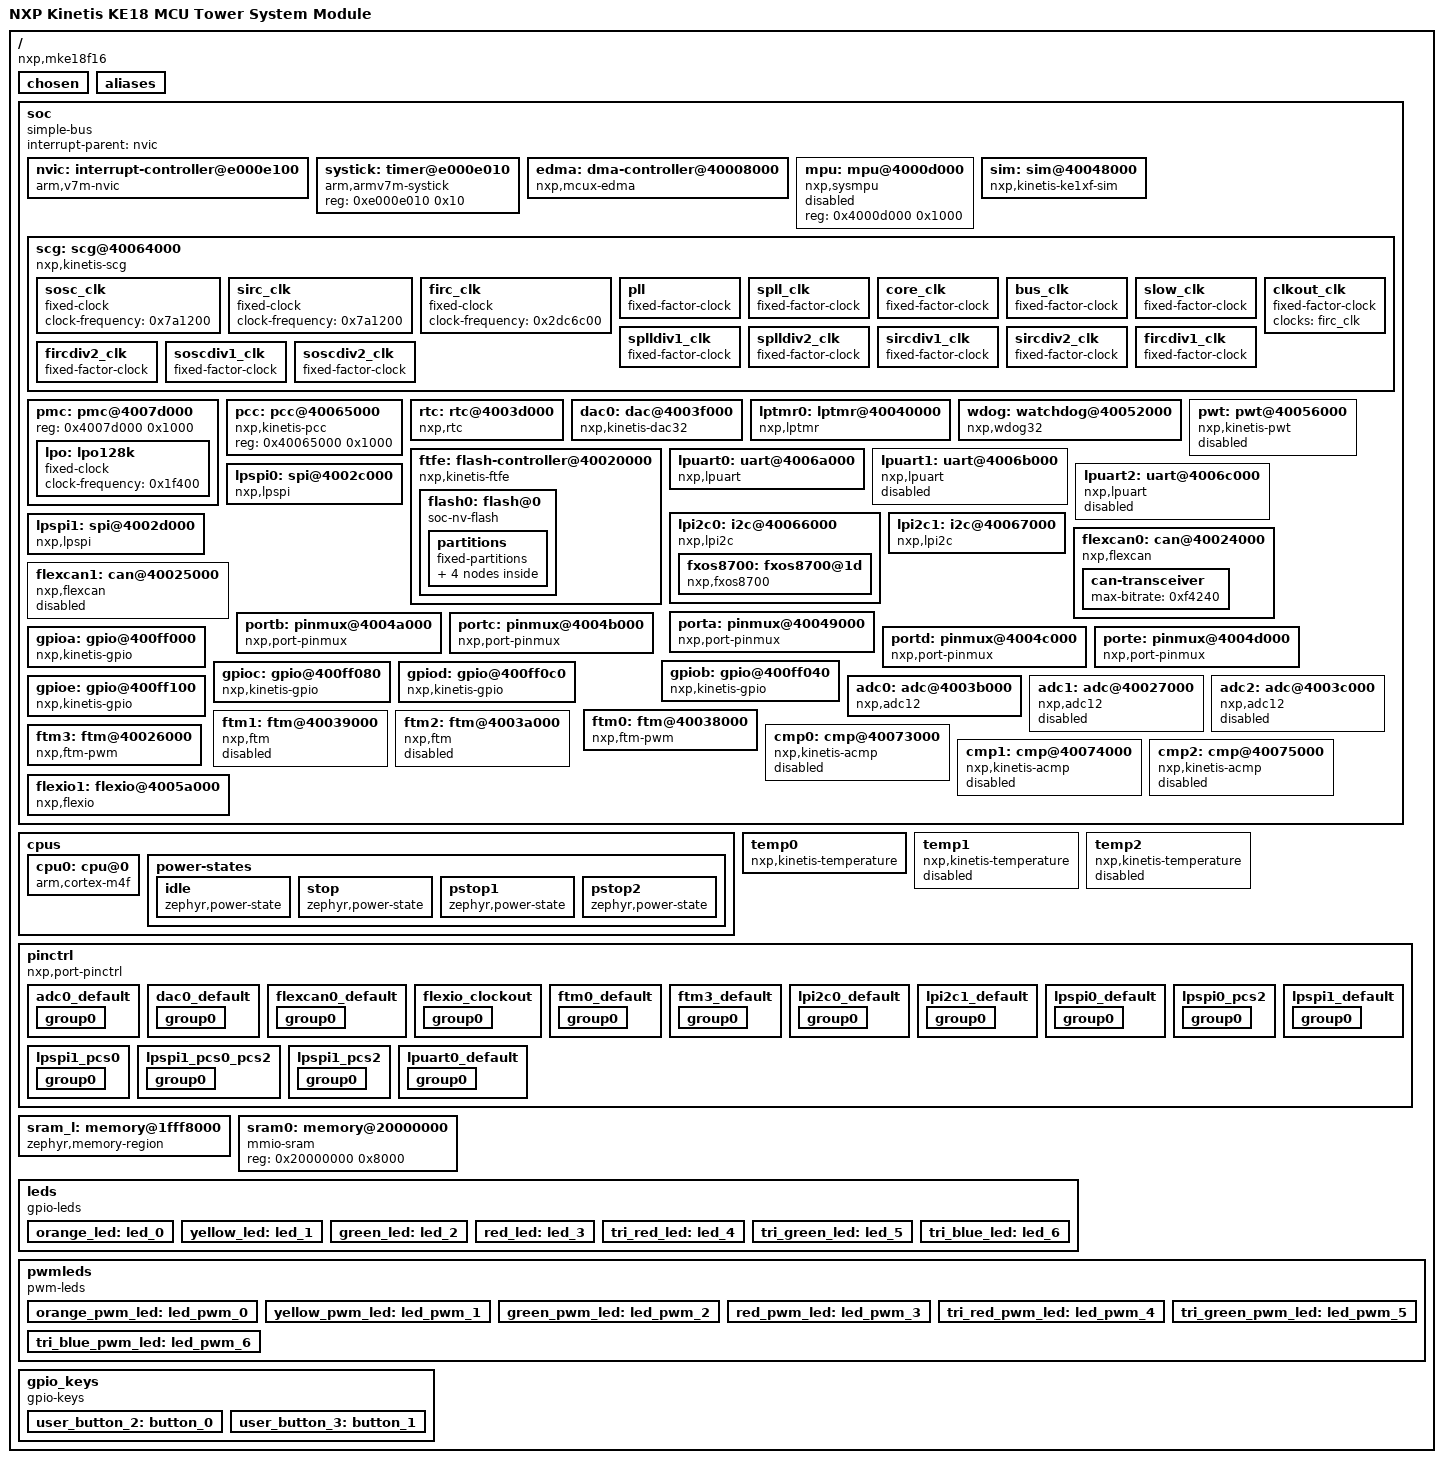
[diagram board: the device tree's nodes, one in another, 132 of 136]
/dts-v1/;

/* node '/' defined in zephyr/dts/common/skeleton.dtsi:9 */
/ {
	#address-cells = < 0x1 >;                           /* in zephyr/dts/common/skeleton.dtsi:10 */
	#size-cells = < 0x1 >;                              /* in zephyr/dts/common/skeleton.dtsi:11 */
	model = "NXP Kinetis KE18 MCU Tower System Module"; /* in zephyr/boards/nxp/twr_ke18f/twr_ke18f.dts:16 */
	compatible = "nxp,mke18f16",
	             "nxp,ke18f",
	             "nxp,ke1xf";                           /* in zephyr/boards/nxp/twr_ke18f/twr_ke18f.dts:17 */

	/* node '/chosen' defined in zephyr/dts/common/skeleton.dtsi:13 */
	chosen {
		zephyr,flash-controller = &ftfe;          /* in zephyr/dts/arm/nxp/nxp_ke1xf.dtsi:20 */
		zephyr,sram = &sram0;                     /* in zephyr/boards/nxp/twr_ke18f/twr_ke18f.dts:48 */
		zephyr,flash = &flash0;                   /* in zephyr/boards/nxp/twr_ke18f/twr_ke18f.dts:49 */
		zephyr,code-partition = &slot0_partition; /* in zephyr/boards/nxp/twr_ke18f/twr_ke18f.dts:50 */
		zephyr,uart-mcumgr = &lpuart0;            /* in zephyr/boards/nxp/twr_ke18f/twr_ke18f.dts:51 */
		zephyr,console = &lpuart0;                /* in zephyr/boards/nxp/twr_ke18f/twr_ke18f.dts:52 */
		zephyr,shell-uart = &lpuart0;             /* in zephyr/boards/nxp/twr_ke18f/twr_ke18f.dts:53 */
		zephyr,uart-pipe = &lpuart0;              /* in zephyr/boards/nxp/twr_ke18f/twr_ke18f.dts:54 */
		zephyr,canbus = &flexcan0;                /* in zephyr/boards/nxp/twr_ke18f/twr_ke18f.dts:55 */
	};

	/* node '/aliases' defined in zephyr/dts/common/skeleton.dtsi:15 */
	aliases {
		watchdog0 = &wdog;                  /* in zephyr/dts/arm/nxp/nxp_ke1xf.dtsi:16 */
		led0 = &orange_led;                 /* in zephyr/boards/nxp/twr_ke18f/twr_ke18f.dts:20 */
		led1 = &yellow_led;                 /* in zephyr/boards/nxp/twr_ke18f/twr_ke18f.dts:21 */
		led2 = &green_led;                  /* in zephyr/boards/nxp/twr_ke18f/twr_ke18f.dts:22 */
		led3 = &red_led;                    /* in zephyr/boards/nxp/twr_ke18f/twr_ke18f.dts:23 */
		led4 = &tri_red_led;                /* in zephyr/boards/nxp/twr_ke18f/twr_ke18f.dts:24 */
		led5 = &tri_green_led;              /* in zephyr/boards/nxp/twr_ke18f/twr_ke18f.dts:25 */
		led6 = &tri_blue_led;               /* in zephyr/boards/nxp/twr_ke18f/twr_ke18f.dts:26 */
		pwm-led0 = &orange_pwm_led;         /* in zephyr/boards/nxp/twr_ke18f/twr_ke18f.dts:27 */
		pwm-led1 = &yellow_pwm_led;         /* in zephyr/boards/nxp/twr_ke18f/twr_ke18f.dts:28 */
		pwm-led2 = &green_pwm_led;          /* in zephyr/boards/nxp/twr_ke18f/twr_ke18f.dts:29 */
		pwm-led3 = &red_pwm_led;            /* in zephyr/boards/nxp/twr_ke18f/twr_ke18f.dts:30 */
		red-pwm-led = &tri_red_pwm_led;     /* in zephyr/boards/nxp/twr_ke18f/twr_ke18f.dts:31 */
		green-pwm-led = &tri_green_pwm_led; /* in zephyr/boards/nxp/twr_ke18f/twr_ke18f.dts:32 */
		blue-pwm-led = &tri_blue_pwm_led;   /* in zephyr/boards/nxp/twr_ke18f/twr_ke18f.dts:33 */
		sw0 = &user_button_3;               /* in zephyr/boards/nxp/twr_ke18f/twr_ke18f.dts:34 */
		sw1 = &user_button_2;               /* in zephyr/boards/nxp/twr_ke18f/twr_ke18f.dts:35 */
		magn0 = &fxos8700;                  /* in zephyr/boards/nxp/twr_ke18f/twr_ke18f.dts:36 */
		accel0 = &fxos8700;                 /* in zephyr/boards/nxp/twr_ke18f/twr_ke18f.dts:37 */
		mcuboot-button0 = &user_button_3;   /* in zephyr/boards/nxp/twr_ke18f/twr_ke18f.dts:38 */
	};

	/* node '/soc' defined in zephyr/dts/arm/armv7-m.dtsi:6 */
	soc {
		#address-cells = < 0x1 >;     /* in zephyr/dts/arm/armv7-m.dtsi:7 */
		#size-cells = < 0x1 >;        /* in zephyr/dts/arm/armv7-m.dtsi:8 */
		compatible = "simple-bus";    /* in zephyr/dts/arm/armv7-m.dtsi:9 */
		interrupt-parent = < &nvic >; /* in zephyr/dts/arm/armv7-m.dtsi:10 */
		ranges;                       /* in zephyr/dts/arm/armv7-m.dtsi:11 */

		/* node '/soc/interrupt-controller@e000e100' defined in zephyr/dts/arm/armv7-m.dtsi:13 */
		nvic: interrupt-controller@e000e100 {
			#address-cells = < 0x1 >;            /* in zephyr/dts/arm/armv7-m.dtsi:14 */
			compatible = "arm,v7m-nvic";         /* in zephyr/dts/arm/armv7-m.dtsi:15 */
			reg = < 0xe000e100 0xc00 >;          /* in zephyr/dts/arm/armv7-m.dtsi:16 */
			interrupt-controller;                /* in zephyr/dts/arm/armv7-m.dtsi:17 */
			#interrupt-cells = < 0x2 >;          /* in zephyr/dts/arm/armv7-m.dtsi:18 */
			arm,num-irq-priority-bits = < 0x4 >; /* in zephyr/dts/arm/nxp/nxp_ke1xf.dtsi:612 */
			phandle = < 0x1 >;                   /* in zephyr/dts/arm/armv7-m.dtsi:10 */
		};

		/* node '/soc/timer@e000e010' defined in zephyr/dts/arm/armv7-m.dtsi:21 */
		systick: timer@e000e010 {
			compatible = "arm,armv7m-systick"; /* in zephyr/dts/arm/armv7-m.dtsi:22 */
			reg = < 0xe000e010 0x10 >;         /* in zephyr/dts/arm/armv7-m.dtsi:23 */
		};

		/* node '/soc/dma-controller@40008000' defined in zephyr/dts/arm/nxp/nxp_ke1xf.dtsi:100 */
		edma: dma-controller@40008000 {
			compatible = "nxp,mcux-edma"; /* in zephyr/dts/arm/nxp/nxp_ke1xf.dtsi:101 */
			nxp,version = < 0x2 >;        /* in zephyr/dts/arm/nxp/nxp_ke1xf.dtsi:102 */
			dma-channels = < 0x10 >;      /* in zephyr/dts/arm/nxp/nxp_ke1xf.dtsi:103 */
			dma-requests = < 0x40 >;      /* in zephyr/dts/arm/nxp/nxp_ke1xf.dtsi:104 */
			nxp,mem2mem;                  /* in zephyr/dts/arm/nxp/nxp_ke1xf.dtsi:105 */
			reg = < 0x40008000 0x1000 >,
			      < 0x40021000 0x1000 >;  /* in zephyr/dts/arm/nxp/nxp_ke1xf.dtsi:106 */
			interrupts = < 0x0 0x0 >,
			             < 0x1 0x0 >,
			             < 0x2 0x0 >,
			             < 0x3 0x0 >,
			             < 0x4 0x0 >,
			             < 0x5 0x0 >,
			             < 0x6 0x0 >,
			             < 0x7 0x0 >,
			             < 0x8 0x0 >,
			             < 0x9 0x0 >,
			             < 0xa 0x0 >,
			             < 0xb 0x0 >,
			             < 0xc 0x0 >,
			             < 0xd 0x0 >,
			             < 0xe 0x0 >,
			             < 0xf 0x0 >,
			             < 0x10 0x0 >;    /* in zephyr/dts/arm/nxp/nxp_ke1xf.dtsi:107 */
			#dma-cells = < 0x2 >;         /* in zephyr/dts/arm/nxp/nxp_ke1xf.dtsi:113 */
			status = "okay";              /* in zephyr/boards/nxp/twr_ke18f/twr_ke18f.dts:342 */
			phandle = < 0xc >;            /* in zephyr/dts/arm/nxp/nxp_ke1xf.dtsi:333 */
		};

		/* node '/soc/mpu@4000d000' defined in zephyr/dts/arm/nxp/nxp_ke1xf.dtsi:116 */
		mpu: mpu@4000d000 {
			compatible = "nxp,sysmpu";   /* in zephyr/dts/arm/nxp/nxp_ke1xf.dtsi:117 */
			reg = < 0x4000d000 0x1000 >; /* in zephyr/dts/arm/nxp/nxp_ke1xf.dtsi:118 */
			status = "disabled";         /* in zephyr/dts/arm/nxp/nxp_ke1xf.dtsi:119 */
		};

		/* node '/soc/sim@40048000' defined in zephyr/dts/arm/nxp/nxp_ke1xf.dtsi:122 */
		sim: sim@40048000 {
			compatible = "nxp,kinetis-ke1xf-sim"; /* in zephyr/dts/arm/nxp/nxp_ke1xf.dtsi:123 */
			reg = < 0x40048000 0x1000 >;          /* in zephyr/dts/arm/nxp/nxp_ke1xf.dtsi:124 */
			clkout-source = < 0x1 >;              /* in zephyr/boards/nxp/twr_ke18f/twr_ke18f.dts:167 */
			clkout-divider = < 0x0 >;             /* in zephyr/boards/nxp/twr_ke18f/twr_ke18f.dts:168 */
		};

		/* node '/soc/scg@40064000' defined in zephyr/dts/arm/nxp/nxp_ke1xf.dtsi:127 */
		scg: scg@40064000 {
			compatible = "nxp,kinetis-scg"; /* in zephyr/dts/arm/nxp/nxp_ke1xf.dtsi:128 */
			reg = < 0x40064000 0x1000 >;    /* in zephyr/dts/arm/nxp/nxp_ke1xf.dtsi:129 */
			#clock-cells = < 0x1 >;         /* in zephyr/dts/arm/nxp/nxp_ke1xf.dtsi:130 */
			sosc-mode = < 0x4 >;            /* in zephyr/boards/nxp/twr_ke18f/twr_ke18f.dts:172 */
			phandle = < 0x8 >;              /* in zephyr/dts/arm/nxp/nxp_ke1xf.dtsi:280 */

			/* node '/soc/scg@40064000/sosc_clk' defined in zephyr/dts/arm/nxp/nxp_ke1xf.dtsi:132 */
			sosc_clk: sosc_clk {
				compatible = "fixed-clock";     /* in zephyr/dts/arm/nxp/nxp_ke1xf.dtsi:133 */
				#clock-cells = < 0x0 >;         /* in zephyr/dts/arm/nxp/nxp_ke1xf.dtsi:135 */
				status = "okay";                /* in zephyr/boards/nxp/twr_ke18f/twr_ke18f.dts:175 */
				clock-frequency = < 0x7a1200 >; /* in zephyr/boards/nxp/twr_ke18f/twr_ke18f.dts:176 */
				phandle = < 0x2 >;              /* in zephyr/dts/arm/nxp/nxp_ke1xf.dtsi:152 */
			};

			/* node '/soc/scg@40064000/sirc_clk' defined in zephyr/dts/arm/nxp/nxp_ke1xf.dtsi:138 */
			sirc_clk: sirc_clk {
				compatible = "fixed-clock";     /* in zephyr/dts/arm/nxp/nxp_ke1xf.dtsi:139 */
				clock-frequency = < 0x7a1200 >; /* in zephyr/dts/arm/nxp/nxp_ke1xf.dtsi:140 */
				#clock-cells = < 0x0 >;         /* in zephyr/dts/arm/nxp/nxp_ke1xf.dtsi:141 */
				phandle = < 0x7 >;              /* in zephyr/dts/arm/nxp/nxp_ke1xf.dtsi:209 */
			};

			/* node '/soc/scg@40064000/firc_clk' defined in zephyr/dts/arm/nxp/nxp_ke1xf.dtsi:144 */
			firc_clk: firc_clk {
				compatible = "fixed-clock";      /* in zephyr/dts/arm/nxp/nxp_ke1xf.dtsi:145 */
				clock-frequency = < 0x2dc6c00 >; /* in zephyr/dts/arm/nxp/nxp_ke1xf.dtsi:146 */
				#clock-cells = < 0x0 >;          /* in zephyr/dts/arm/nxp/nxp_ke1xf.dtsi:147 */
				phandle = < 0x6 >;               /* in zephyr/dts/arm/nxp/nxp_ke1xf.dtsi:189 */
			};

			/* node '/soc/scg@40064000/pll' defined in zephyr/dts/arm/nxp/nxp_ke1xf.dtsi:150 */
			pll: pll {
				compatible = "fixed-factor-clock"; /* in zephyr/dts/arm/nxp/nxp_ke1xf.dtsi:151 */
				clocks = < &sosc_clk >;            /* in zephyr/dts/arm/nxp/nxp_ke1xf.dtsi:152 */
				clock-div = < 0x1 >;               /* in zephyr/dts/arm/nxp/nxp_ke1xf.dtsi:153 */
				#clock-cells = < 0x0 >;            /* in zephyr/dts/arm/nxp/nxp_ke1xf.dtsi:155 */
				clock-mult = < 0x1e >;             /* in zephyr/boards/nxp/twr_ke18f/twr_ke18f.dts:180 */
				phandle = < 0x3 >;                 /* in zephyr/dts/arm/nxp/nxp_ke1xf.dtsi:160 */
			};

			/* node '/soc/scg@40064000/spll_clk' defined in zephyr/dts/arm/nxp/nxp_ke1xf.dtsi:158 */
			spll_clk: spll_clk {
				compatible = "fixed-factor-clock"; /* in zephyr/dts/arm/nxp/nxp_ke1xf.dtsi:159 */
				clocks = < &pll >;                 /* in zephyr/dts/arm/nxp/nxp_ke1xf.dtsi:160 */
				clock-div = < 0x2 >;               /* in zephyr/dts/arm/nxp/nxp_ke1xf.dtsi:161 */
				#clock-cells = < 0x0 >;            /* in zephyr/dts/arm/nxp/nxp_ke1xf.dtsi:162 */
				phandle = < 0x4 >;                 /* in zephyr/boards/nxp/twr_ke18f/twr_ke18f.dts:184 */
			};

			/* node '/soc/scg@40064000/core_clk' defined in zephyr/dts/arm/nxp/nxp_ke1xf.dtsi:165 */
			core_clk: core_clk {
				compatible = "fixed-factor-clock"; /* in zephyr/dts/arm/nxp/nxp_ke1xf.dtsi:166 */
				clock-div = < 0x1 >;               /* in zephyr/dts/arm/nxp/nxp_ke1xf.dtsi:168 */
				#clock-cells = < 0x0 >;            /* in zephyr/dts/arm/nxp/nxp_ke1xf.dtsi:169 */
				clocks = < &spll_clk >;            /* in zephyr/boards/nxp/twr_ke18f/twr_ke18f.dts:184 */
				phandle = < 0x5 >;                 /* in zephyr/dts/arm/nxp/nxp_ke1xf.dtsi:174 */
			};

			/* node '/soc/scg@40064000/bus_clk' defined in zephyr/dts/arm/nxp/nxp_ke1xf.dtsi:172 */
			bus_clk: bus_clk {
				compatible = "fixed-factor-clock"; /* in zephyr/dts/arm/nxp/nxp_ke1xf.dtsi:173 */
				clocks = < &core_clk >;            /* in zephyr/dts/arm/nxp/nxp_ke1xf.dtsi:174 */
				#clock-cells = < 0x0 >;            /* in zephyr/dts/arm/nxp/nxp_ke1xf.dtsi:176 */
				clock-div = < 0x2 >;               /* in zephyr/boards/nxp/twr_ke18f/twr_ke18f.dts:188 */
			};

			/* node '/soc/scg@40064000/slow_clk' defined in zephyr/dts/arm/nxp/nxp_ke1xf.dtsi:179 */
			slow_clk: slow_clk {
				compatible = "fixed-factor-clock"; /* in zephyr/dts/arm/nxp/nxp_ke1xf.dtsi:180 */
				clocks = < &core_clk >;            /* in zephyr/dts/arm/nxp/nxp_ke1xf.dtsi:181 */
				#clock-cells = < 0x0 >;            /* in zephyr/dts/arm/nxp/nxp_ke1xf.dtsi:183 */
				clock-div = < 0x5 >;               /* in zephyr/boards/nxp/twr_ke18f/twr_ke18f.dts:192 */
			};

			/* node '/soc/scg@40064000/clkout_clk' defined in zephyr/dts/arm/nxp/nxp_ke1xf.dtsi:186 */
			clkout_clk: clkout_clk {
				compatible = "fixed-factor-clock"; /* in zephyr/dts/arm/nxp/nxp_ke1xf.dtsi:187 */
				clocks = < &firc_clk >;            /* in zephyr/dts/arm/nxp/nxp_ke1xf.dtsi:189 */
				#clock-cells = < 0x0 >;            /* in zephyr/dts/arm/nxp/nxp_ke1xf.dtsi:190 */
				status = "okay";                   /* in zephyr/boards/nxp/twr_ke18f/twr_ke18f.dts:196 */
			};

			/* node '/soc/scg@40064000/splldiv1_clk' defined in zephyr/dts/arm/nxp/nxp_ke1xf.dtsi:193 */
			splldiv1_clk: splldiv1_clk {
				compatible = "fixed-factor-clock"; /* in zephyr/dts/arm/nxp/nxp_ke1xf.dtsi:194 */
				clocks = < &spll_clk >;            /* in zephyr/dts/arm/nxp/nxp_ke1xf.dtsi:195 */
				#clock-cells = < 0x0 >;            /* in zephyr/dts/arm/nxp/nxp_ke1xf.dtsi:197 */
				clock-div = < 0x1 >;               /* in zephyr/boards/nxp/twr_ke18f/twr_ke18f.dts:200 */
			};

			/* node '/soc/scg@40064000/splldiv2_clk' defined in zephyr/dts/arm/nxp/nxp_ke1xf.dtsi:200 */
			splldiv2_clk: splldiv2_clk {
				compatible = "fixed-factor-clock"; /* in zephyr/dts/arm/nxp/nxp_ke1xf.dtsi:201 */
				clocks = < &spll_clk >;            /* in zephyr/dts/arm/nxp/nxp_ke1xf.dtsi:202 */
				#clock-cells = < 0x0 >;            /* in zephyr/dts/arm/nxp/nxp_ke1xf.dtsi:204 */
				clock-div = < 0x2 >;               /* in zephyr/boards/nxp/twr_ke18f/twr_ke18f.dts:204 */
			};

			/* node '/soc/scg@40064000/sircdiv1_clk' defined in zephyr/dts/arm/nxp/nxp_ke1xf.dtsi:207 */
			sircdiv1_clk: sircdiv1_clk {
				compatible = "fixed-factor-clock"; /* in zephyr/dts/arm/nxp/nxp_ke1xf.dtsi:208 */
				clocks = < &sirc_clk >;            /* in zephyr/dts/arm/nxp/nxp_ke1xf.dtsi:209 */
				#clock-cells = < 0x0 >;            /* in zephyr/dts/arm/nxp/nxp_ke1xf.dtsi:211 */
				clock-div = < 0x1 >;               /* in zephyr/boards/nxp/twr_ke18f/twr_ke18f.dts:208 */
			};

			/* node '/soc/scg@40064000/sircdiv2_clk' defined in zephyr/dts/arm/nxp/nxp_ke1xf.dtsi:214 */
			sircdiv2_clk: sircdiv2_clk {
				compatible = "fixed-factor-clock"; /* in zephyr/dts/arm/nxp/nxp_ke1xf.dtsi:215 */
				clocks = < &sirc_clk >;            /* in zephyr/dts/arm/nxp/nxp_ke1xf.dtsi:216 */
				#clock-cells = < 0x0 >;            /* in zephyr/dts/arm/nxp/nxp_ke1xf.dtsi:218 */
				clock-div = < 0x2 >;               /* in zephyr/boards/nxp/twr_ke18f/twr_ke18f.dts:212 */
			};

			/* node '/soc/scg@40064000/fircdiv1_clk' defined in zephyr/dts/arm/nxp/nxp_ke1xf.dtsi:221 */
			fircdiv1_clk: fircdiv1_clk {
				compatible = "fixed-factor-clock"; /* in zephyr/dts/arm/nxp/nxp_ke1xf.dtsi:222 */
				clocks = < &firc_clk >;            /* in zephyr/dts/arm/nxp/nxp_ke1xf.dtsi:223 */
				#clock-cells = < 0x0 >;            /* in zephyr/dts/arm/nxp/nxp_ke1xf.dtsi:225 */
				clock-div = < 0x1 >;               /* in zephyr/boards/nxp/twr_ke18f/twr_ke18f.dts:216 */
			};

			/* node '/soc/scg@40064000/fircdiv2_clk' defined in zephyr/dts/arm/nxp/nxp_ke1xf.dtsi:228 */
			fircdiv2_clk: fircdiv2_clk {
				compatible = "fixed-factor-clock"; /* in zephyr/dts/arm/nxp/nxp_ke1xf.dtsi:229 */
				clocks = < &firc_clk >;            /* in zephyr/dts/arm/nxp/nxp_ke1xf.dtsi:230 */
				#clock-cells = < 0x0 >;            /* in zephyr/dts/arm/nxp/nxp_ke1xf.dtsi:232 */
				clock-div = < 0x1 >;               /* in zephyr/boards/nxp/twr_ke18f/twr_ke18f.dts:220 */
			};

			/* node '/soc/scg@40064000/soscdiv1_clk' defined in zephyr/dts/arm/nxp/nxp_ke1xf.dtsi:235 */
			soscdiv1_clk: soscdiv1_clk {
				compatible = "fixed-factor-clock"; /* in zephyr/dts/arm/nxp/nxp_ke1xf.dtsi:236 */
				clocks = < &sosc_clk >;            /* in zephyr/dts/arm/nxp/nxp_ke1xf.dtsi:237 */
				#clock-cells = < 0x0 >;            /* in zephyr/dts/arm/nxp/nxp_ke1xf.dtsi:239 */
				clock-div = < 0x1 >;               /* in zephyr/boards/nxp/twr_ke18f/twr_ke18f.dts:224 */
			};

			/* node '/soc/scg@40064000/soscdiv2_clk' defined in zephyr/dts/arm/nxp/nxp_ke1xf.dtsi:242 */
			soscdiv2_clk: soscdiv2_clk {
				compatible = "fixed-factor-clock"; /* in zephyr/dts/arm/nxp/nxp_ke1xf.dtsi:243 */
				clocks = < &sosc_clk >;            /* in zephyr/dts/arm/nxp/nxp_ke1xf.dtsi:244 */
				#clock-cells = < 0x0 >;            /* in zephyr/dts/arm/nxp/nxp_ke1xf.dtsi:246 */
				clock-div = < 0x1 >;               /* in zephyr/boards/nxp/twr_ke18f/twr_ke18f.dts:228 */
			};
		};

		/* node '/soc/pmc@4007d000' defined in zephyr/dts/arm/nxp/nxp_ke1xf.dtsi:250 */
		pmc: pmc@4007d000 {
			reg = < 0x4007d000 0x1000 >; /* in zephyr/dts/arm/nxp/nxp_ke1xf.dtsi:251 */

			/* node '/soc/pmc@4007d000/lpo128k' defined in zephyr/dts/arm/nxp/nxp_ke1xf.dtsi:253 */
			lpo: lpo128k {
				compatible = "fixed-clock";    /* in zephyr/dts/arm/nxp/nxp_ke1xf.dtsi:255 */
				clock-frequency = < 0x1f400 >; /* in zephyr/dts/arm/nxp/nxp_ke1xf.dtsi:256 */
				#clock-cells = < 0x0 >;        /* in zephyr/dts/arm/nxp/nxp_ke1xf.dtsi:257 */
				phandle = < 0xa >;             /* in zephyr/dts/arm/nxp/nxp_ke1xf.dtsi:301 */
			};
		};

		/* node '/soc/pcc@40065000' defined in zephyr/dts/arm/nxp/nxp_ke1xf.dtsi:261 */
		pcc: pcc@40065000 {
			compatible = "nxp,kinetis-pcc"; /* in zephyr/dts/arm/nxp/nxp_ke1xf.dtsi:262 */
			reg = < 0x40065000 0x1000 >;    /* in zephyr/dts/arm/nxp/nxp_ke1xf.dtsi:263 */
			#clock-cells = < 0x2 >;         /* in zephyr/dts/arm/nxp/nxp_ke1xf.dtsi:264 */
			phandle = < 0xb >;              /* in zephyr/dts/arm/nxp/nxp_ke1xf.dtsi:332 */
		};

		/* node '/soc/rtc@4003d000' defined in zephyr/dts/arm/nxp/nxp_ke1xf.dtsi:267 */
		rtc: rtc@4003d000 {
			compatible = "nxp,rtc";       /* in zephyr/dts/arm/nxp/nxp_ke1xf.dtsi:268 */
			reg = < 0x4003d000 0x1000 >;  /* in zephyr/dts/arm/nxp/nxp_ke1xf.dtsi:269 */
			interrupts = < 0x2e 0x0 >,
			             < 0x2f 0x0 >;    /* in zephyr/dts/arm/nxp/nxp_ke1xf.dtsi:270 */
			interrupt-names = "alarm",
			                  "seconds";  /* in zephyr/dts/arm/nxp/nxp_ke1xf.dtsi:271 */
			clock-frequency = < 0x8000 >; /* in zephyr/dts/arm/nxp/nxp_ke1xf.dtsi:272 */
			prescaler = < 0x8000 >;       /* in zephyr/dts/arm/nxp/nxp_ke1xf.dtsi:273 */
		};

		/* node '/soc/dac@4003f000' defined in zephyr/dts/arm/nxp/nxp_ke1xf.dtsi:276 */
		dac0: dac@4003f000 {
			compatible = "nxp,kinetis-dac32"; /* in zephyr/dts/arm/nxp/nxp_ke1xf.dtsi:277 */
			reg = < 0x4003f000 0x1000 >;      /* in zephyr/dts/arm/nxp/nxp_ke1xf.dtsi:278 */
			interrupts = < 0x38 0x0 >;        /* in zephyr/dts/arm/nxp/nxp_ke1xf.dtsi:279 */
			clocks = < &scg 0x1 >;            /* in zephyr/dts/arm/nxp/nxp_ke1xf.dtsi:280 */
			voltage-reference = < 0x1 >;      /* in zephyr/dts/arm/nxp/nxp_ke1xf.dtsi:281 */
			buffered;                         /* in zephyr/dts/arm/nxp/nxp_ke1xf.dtsi:282 */
			#io-channel-cells = < 0x1 >;      /* in zephyr/dts/arm/nxp/nxp_ke1xf.dtsi:284 */
			status = "okay";                  /* in zephyr/boards/nxp/twr_ke18f/twr_ke18f.dts:294 */
			pinctrl-0 = < &dac0_default >;    /* in zephyr/boards/nxp/twr_ke18f/twr_ke18f.dts:295 */
			pinctrl-names = "default";        /* in zephyr/boards/nxp/twr_ke18f/twr_ke18f.dts:296 */
		};

		/* node '/soc/lptmr@40040000' defined in zephyr/dts/arm/nxp/nxp_ke1xf.dtsi:287 */
		lptmr0: lptmr@40040000 {
			compatible = "nxp,lptmr";         /* in zephyr/dts/arm/nxp/nxp_ke1xf.dtsi:288 */
			reg = < 0x40040000 0x1000 >;      /* in zephyr/dts/arm/nxp/nxp_ke1xf.dtsi:289 */
			interrupts = < 0x3a 0x0 >;        /* in zephyr/dts/arm/nxp/nxp_ke1xf.dtsi:290 */
			clock-frequency = < 0x1f400 >;    /* in zephyr/dts/arm/nxp/nxp_ke1xf.dtsi:291 */
			prescale-glitch-filter = < 0x0 >; /* in zephyr/dts/arm/nxp/nxp_ke1xf.dtsi:292 */
			clk-source = < 0x1 >;             /* in zephyr/dts/arm/nxp/nxp_ke1xf.dtsi:293 */
			resolution = < 0x10 >;            /* in zephyr/dts/arm/nxp/nxp_ke1xf.dtsi:294 */
		};

		/* node '/soc/watchdog@40052000' defined in zephyr/dts/arm/nxp/nxp_ke1xf.dtsi:297 */
		wdog: watchdog@40052000 {
			compatible = "nxp,wdog32";   /* in zephyr/dts/arm/nxp/nxp_ke1xf.dtsi:298 */
			reg = < 0x40052000 0x1000 >; /* in zephyr/dts/arm/nxp/nxp_ke1xf.dtsi:299 */
			interrupts = < 0x16 0x0 >;   /* in zephyr/dts/arm/nxp/nxp_ke1xf.dtsi:300 */
			clocks = < &lpo >;           /* in zephyr/dts/arm/nxp/nxp_ke1xf.dtsi:301 */
			clk-source = < 0x1 >;        /* in zephyr/dts/arm/nxp/nxp_ke1xf.dtsi:302 */
			clk-divider = < 0x100 >;     /* in zephyr/dts/arm/nxp/nxp_ke1xf.dtsi:303 */
		};

		/* node '/soc/pwt@40056000' defined in zephyr/dts/arm/nxp/nxp_ke1xf.dtsi:306 */
		pwt: pwt@40056000 {
			compatible = "nxp,kinetis-pwt"; /* in zephyr/dts/arm/nxp/nxp_ke1xf.dtsi:307 */
			reg = < 0x40056000 0x1000 >;    /* in zephyr/dts/arm/nxp/nxp_ke1xf.dtsi:308 */
			interrupts = < 0x1d 0x0 >;      /* in zephyr/dts/arm/nxp/nxp_ke1xf.dtsi:309 */
			clocks = < &scg 0x1 >;          /* in zephyr/dts/arm/nxp/nxp_ke1xf.dtsi:310 */
			prescaler = < 0x1 >;            /* in zephyr/dts/arm/nxp/nxp_ke1xf.dtsi:311 */
			status = "disabled";            /* in zephyr/dts/arm/nxp/nxp_ke1xf.dtsi:312 */
			#pwm-cells = < 0x3 >;           /* in zephyr/dts/arm/nxp/nxp_ke1xf.dtsi:314 */
		};

		/* node '/soc/flash-controller@40020000' defined in zephyr/dts/arm/nxp/nxp_ke1xf.dtsi:317 */
		ftfe: flash-controller@40020000 {
			compatible = "nxp,kinetis-ftfe";      /* in zephyr/dts/arm/nxp/nxp_ke1xf.dtsi:318 */
			reg = < 0x40020000 0x1000 >;          /* in zephyr/dts/arm/nxp/nxp_ke1xf.dtsi:319 */
			interrupts = < 0x12 0x0 >,
			             < 0x13 0x0 >;            /* in zephyr/dts/arm/nxp/nxp_ke1xf.dtsi:320 */
			interrupt-names = "command-complete",
			                  "read-collision";   /* in zephyr/dts/arm/nxp/nxp_ke1xf.dtsi:321 */
			#address-cells = < 0x1 >;             /* in zephyr/dts/arm/nxp/nxp_ke1xf.dtsi:323 */
			#size-cells = < 0x1 >;                /* in zephyr/dts/arm/nxp/nxp_ke1xf.dtsi:324 */

			/* node '/soc/flash-controller@40020000/flash@0' defined in zephyr/dts/arm/nxp/nxp_ke1xf512vlx16.dtsi:34 */
			flash0: flash@0 {
				compatible = "soc-nv-flash";   /* in zephyr/dts/arm/nxp/nxp_ke1xf512vlx16.dtsi:35 */
				reg = < 0x0 0x80000 >;         /* in zephyr/dts/arm/nxp/nxp_ke1xf512vlx16.dtsi:36 */
				erase-block-size = < 0x1000 >; /* in zephyr/dts/arm/nxp/nxp_ke1xf512vlx16.dtsi:37 */
				write-block-size = < 0x8 >;    /* in zephyr/dts/arm/nxp/nxp_ke1xf512vlx16.dtsi:38 */

				/* node '/soc/flash-controller@40020000/flash@0/partitions' defined in zephyr/boards/nxp/twr_ke18f/twr_ke18f.dts:350 */
				partitions {
					compatible = "fixed-partitions"; /* in zephyr/boards/nxp/twr_ke18f/twr_ke18f.dts:351 */
					#address-cells = < 0x1 >;        /* in zephyr/boards/nxp/twr_ke18f/twr_ke18f.dts:352 */
					#size-cells = < 0x1 >;           /* in zephyr/boards/nxp/twr_ke18f/twr_ke18f.dts:353 */

					/* node '/soc/flash-controller@40020000/flash@0/partitions/partition@0' defined in zephyr/boards/nxp/twr_ke18f/twr_ke18f.dts:359 */
					boot_partition: partition@0 {
						label = "mcuboot";     /* in zephyr/boards/nxp/twr_ke18f/twr_ke18f.dts:360 */
						reg = < 0x0 0x10000 >; /* in zephyr/boards/nxp/twr_ke18f/twr_ke18f.dts:361 */
						read-only;             /* in zephyr/boards/nxp/twr_ke18f/twr_ke18f.dts:362 */
					};

					/* node '/soc/flash-controller@40020000/flash@0/partitions/partition@10000' defined in zephyr/boards/nxp/twr_ke18f/twr_ke18f.dts:365 */
					slot0_partition: partition@10000 {
						label = "image-0";         /* in zephyr/boards/nxp/twr_ke18f/twr_ke18f.dts:366 */
						reg = < 0x10000 0x33000 >; /* in zephyr/boards/nxp/twr_ke18f/twr_ke18f.dts:367 */
					};

					/* node '/soc/flash-controller@40020000/flash@0/partitions/partition@43000' defined in zephyr/boards/nxp/twr_ke18f/twr_ke18f.dts:370 */
					slot1_partition: partition@43000 {
						label = "image-1";         /* in zephyr/boards/nxp/twr_ke18f/twr_ke18f.dts:371 */
						reg = < 0x43000 0x33000 >; /* in zephyr/boards/nxp/twr_ke18f/twr_ke18f.dts:372 */
					};

					/* node '/soc/flash-controller@40020000/flash@0/partitions/partition@76000' defined in zephyr/boards/nxp/twr_ke18f/twr_ke18f.dts:375 */
					storage_partition: partition@76000 {
						label = "storage";        /* in zephyr/boards/nxp/twr_ke18f/twr_ke18f.dts:376 */
						reg = < 0x76000 0xa000 >; /* in zephyr/boards/nxp/twr_ke18f/twr_ke18f.dts:377 */
					};
				};
			};
		};

		/* node '/soc/uart@4006a000' defined in zephyr/dts/arm/nxp/nxp_ke1xf.dtsi:327 */
		lpuart0: uart@4006a000 {
			compatible = "nxp,lpuart";        /* in zephyr/dts/arm/nxp/nxp_ke1xf.dtsi:328 */
			reg = < 0x4006a000 0x1000 >;      /* in zephyr/dts/arm/nxp/nxp_ke1xf.dtsi:329 */
			interrupts = < 0x1f 0x0 >,
			             < 0x20 0x0 >;        /* in zephyr/dts/arm/nxp/nxp_ke1xf.dtsi:330 */
			interrupt-names = "transmit",
			                  "receive";      /* in zephyr/dts/arm/nxp/nxp_ke1xf.dtsi:331 */
			clocks = < &pcc 0x1a8 0x3 >;      /* in zephyr/dts/arm/nxp/nxp_ke1xf.dtsi:332 */
			dmas = < &edma 0x1 0x2 >,
			       < &edma 0x2 0x3 >;         /* in zephyr/dts/arm/nxp/nxp_ke1xf.dtsi:333 */
			dma-names = "rx",
			            "tx";                 /* in zephyr/dts/arm/nxp/nxp_ke1xf.dtsi:334 */
			status = "okay";                  /* in zephyr/boards/nxp/twr_ke18f/twr_ke18f.dts:233 */
			current-speed = < 0x1c200 >;      /* in zephyr/boards/nxp/twr_ke18f/twr_ke18f.dts:234 */
			pinctrl-0 = < &lpuart0_default >; /* in zephyr/boards/nxp/twr_ke18f/twr_ke18f.dts:235 */
			pinctrl-names = "default";        /* in zephyr/boards/nxp/twr_ke18f/twr_ke18f.dts:236 */
		};

		/* node '/soc/uart@4006b000' defined in zephyr/dts/arm/nxp/nxp_ke1xf.dtsi:338 */
		lpuart1: uart@4006b000 {
			compatible = "nxp,lpuart";    /* in zephyr/dts/arm/nxp/nxp_ke1xf.dtsi:339 */
			reg = < 0x4006b000 0x1000 >;  /* in zephyr/dts/arm/nxp/nxp_ke1xf.dtsi:340 */
			interrupts = < 0x21 0x0 >,
			             < 0x22 0x0 >;    /* in zephyr/dts/arm/nxp/nxp_ke1xf.dtsi:341 */
			interrupt-names = "transmit",
			                  "receive";  /* in zephyr/dts/arm/nxp/nxp_ke1xf.dtsi:342 */
			clocks = < &pcc 0x1ac 0x3 >;  /* in zephyr/dts/arm/nxp/nxp_ke1xf.dtsi:343 */
			dmas = < &edma 0x3 0x4 >,
			       < &edma 0x4 0x5 >;     /* in zephyr/dts/arm/nxp/nxp_ke1xf.dtsi:344 */
			dma-names = "rx",
			            "tx";             /* in zephyr/dts/arm/nxp/nxp_ke1xf.dtsi:345 */
			status = "disabled";          /* in zephyr/dts/arm/nxp/nxp_ke1xf.dtsi:346 */
		};

		/* node '/soc/uart@4006c000' defined in zephyr/dts/arm/nxp/nxp_ke1xf.dtsi:349 */
		lpuart2: uart@4006c000 {
			compatible = "nxp,lpuart";    /* in zephyr/dts/arm/nxp/nxp_ke1xf.dtsi:350 */
			reg = < 0x4006c000 0x1000 >;  /* in zephyr/dts/arm/nxp/nxp_ke1xf.dtsi:351 */
			interrupts = < 0x23 0x0 >,
			             < 0x24 0x0 >;    /* in zephyr/dts/arm/nxp/nxp_ke1xf.dtsi:352 */
			interrupt-names = "transmit",
			                  "receive";  /* in zephyr/dts/arm/nxp/nxp_ke1xf.dtsi:353 */
			clocks = < &pcc 0x1b0 0x3 >;  /* in zephyr/dts/arm/nxp/nxp_ke1xf.dtsi:354 */
			dmas = < &edma 0x5 0x6 >,
			       < &edma 0x5 0x7 >;     /* in zephyr/dts/arm/nxp/nxp_ke1xf.dtsi:355 */
			dma-names = "rx",
			            "tx";             /* in zephyr/dts/arm/nxp/nxp_ke1xf.dtsi:356 */
			status = "disabled";          /* in zephyr/dts/arm/nxp/nxp_ke1xf.dtsi:357 */
		};

		/* node '/soc/i2c@40066000' defined in zephyr/dts/arm/nxp/nxp_ke1xf.dtsi:360 */
		lpi2c0: i2c@40066000 {
			compatible = "nxp,lpi2c";        /* in zephyr/dts/arm/nxp/nxp_ke1xf.dtsi:361 */
			clock-frequency = < 0x186a0 >;   /* in zephyr/dts/arm/nxp/nxp_ke1xf.dtsi:362 */
			#address-cells = < 0x1 >;        /* in zephyr/dts/arm/nxp/nxp_ke1xf.dtsi:363 */
			#size-cells = < 0x0 >;           /* in zephyr/dts/arm/nxp/nxp_ke1xf.dtsi:364 */
			reg = < 0x40066000 0x1000 >;     /* in zephyr/dts/arm/nxp/nxp_ke1xf.dtsi:365 */
			interrupts = < 0x18 0x0 >;       /* in zephyr/dts/arm/nxp/nxp_ke1xf.dtsi:366 */
			clocks = < &pcc 0x198 0x3 >;     /* in zephyr/dts/arm/nxp/nxp_ke1xf.dtsi:367 */
			status = "okay";                 /* in zephyr/boards/nxp/twr_ke18f/twr_ke18f.dts:258 */
			pinctrl-0 = < &lpi2c0_default >; /* in zephyr/boards/nxp/twr_ke18f/twr_ke18f.dts:259 */
			pinctrl-names = "default";       /* in zephyr/boards/nxp/twr_ke18f/twr_ke18f.dts:260 */
			scl-gpios = < &gpioa 0x3 0x0 >;  /* in zephyr/boards/nxp/twr_ke18f/twr_ke18f.dts:261 */
			sda-gpios = < &gpioa 0x2 0x0 >;  /* in zephyr/boards/nxp/twr_ke18f/twr_ke18f.dts:262 */

			/* node '/soc/i2c@40066000/fxos8700@1d' defined in zephyr/boards/nxp/twr_ke18f/twr_ke18f.dts:264 */
			fxos8700: fxos8700@1d {
				compatible = "nxp,fxos8700";      /* in zephyr/boards/nxp/twr_ke18f/twr_ke18f.dts:265 */
				reg = < 0x1d >;                   /* in zephyr/boards/nxp/twr_ke18f/twr_ke18f.dts:266 */
				reset-gpios = < &gpioc 0xf 0x0 >; /* in zephyr/boards/nxp/twr_ke18f/twr_ke18f.dts:267 */
			};
		};

		/* node '/soc/i2c@40067000' defined in zephyr/dts/arm/nxp/nxp_ke1xf.dtsi:371 */
		lpi2c1: i2c@40067000 {
			compatible = "nxp,lpi2c";        /* in zephyr/dts/arm/nxp/nxp_ke1xf.dtsi:372 */
			clock-frequency = < 0x186a0 >;   /* in zephyr/dts/arm/nxp/nxp_ke1xf.dtsi:373 */
			#address-cells = < 0x1 >;        /* in zephyr/dts/arm/nxp/nxp_ke1xf.dtsi:374 */
			#size-cells = < 0x0 >;           /* in zephyr/dts/arm/nxp/nxp_ke1xf.dtsi:375 */
			reg = < 0x40067000 0x1000 >;     /* in zephyr/dts/arm/nxp/nxp_ke1xf.dtsi:376 */
			interrupts = < 0x19 0x0 >;       /* in zephyr/dts/arm/nxp/nxp_ke1xf.dtsi:377 */
			clocks = < &pcc 0x19c 0x3 >;     /* in zephyr/dts/arm/nxp/nxp_ke1xf.dtsi:378 */
			status = "okay";                 /* in zephyr/boards/nxp/twr_ke18f/twr_ke18f.dts:272 */
			pinctrl-0 = < &lpi2c1_default >; /* in zephyr/boards/nxp/twr_ke18f/twr_ke18f.dts:273 */
			pinctrl-names = "default";       /* in zephyr/boards/nxp/twr_ke18f/twr_ke18f.dts:274 */
			scl-gpios = < &gpiod 0x9 0x0 >;  /* in zephyr/boards/nxp/twr_ke18f/twr_ke18f.dts:275 */
			sda-gpios = < &gpiod 0x8 0x0 >;  /* in zephyr/boards/nxp/twr_ke18f/twr_ke18f.dts:276 */
		};

		/* node '/soc/spi@4002c000' defined in zephyr/dts/arm/nxp/nxp_ke1xf.dtsi:382 */
		lpspi0: spi@4002c000 {
			compatible = "nxp,lpspi";        /* in zephyr/dts/arm/nxp/nxp_ke1xf.dtsi:383 */
			reg = < 0x4002c000 0x1000 >;     /* in zephyr/dts/arm/nxp/nxp_ke1xf.dtsi:384 */
			interrupts = < 0x1a 0x0 >;       /* in zephyr/dts/arm/nxp/nxp_ke1xf.dtsi:385 */
			clocks = < &pcc 0xb0 0x3 >;      /* in zephyr/dts/arm/nxp/nxp_ke1xf.dtsi:386 */
			#address-cells = < 0x1 >;        /* in zephyr/dts/arm/nxp/nxp_ke1xf.dtsi:388 */
			#size-cells = < 0x0 >;           /* in zephyr/dts/arm/nxp/nxp_ke1xf.dtsi:389 */
			tx-fifo-size = < 0x4 >;          /* in zephyr/dts/arm/nxp/nxp_ke1xf.dtsi:390 */
			rx-fifo-size = < 0x4 >;          /* in zephyr/dts/arm/nxp/nxp_ke1xf.dtsi:391 */
			dmas = < &edma 0x0 0xe >,
			       < &edma 0x1 0xf >;        /* in zephyr/boards/nxp/twr_ke18f/twr_ke18f.dts:280 */
			dma-names = "rx",
			            "tx";                /* in zephyr/boards/nxp/twr_ke18f/twr_ke18f.dts:281 */
			status = "okay";                 /* in zephyr/boards/nxp/twr_ke18f/twr_ke18f.dts:282 */
			pinctrl-0 = < &lpspi0_default >; /* in zephyr/boards/nxp/twr_ke18f/twr_ke18f.dts:283 */
			pinctrl-names = "default";       /* in zephyr/boards/nxp/twr_ke18f/twr_ke18f.dts:284 */
		};

		/* node '/soc/spi@4002d000' defined in zephyr/dts/arm/nxp/nxp_ke1xf.dtsi:394 */
		lpspi1: spi@4002d000 {
			compatible = "nxp,lpspi";        /* in zephyr/dts/arm/nxp/nxp_ke1xf.dtsi:395 */
			reg = < 0x4002d000 0x1000 >;     /* in zephyr/dts/arm/nxp/nxp_ke1xf.dtsi:396 */
			interrupts = < 0x1b 0x0 >;       /* in zephyr/dts/arm/nxp/nxp_ke1xf.dtsi:397 */
			clocks = < &pcc 0xb4 0x3 >;      /* in zephyr/dts/arm/nxp/nxp_ke1xf.dtsi:398 */
			#address-cells = < 0x1 >;        /* in zephyr/dts/arm/nxp/nxp_ke1xf.dtsi:400 */
			#size-cells = < 0x0 >;           /* in zephyr/dts/arm/nxp/nxp_ke1xf.dtsi:401 */
			tx-fifo-size = < 0x4 >;          /* in zephyr/dts/arm/nxp/nxp_ke1xf.dtsi:402 */
			rx-fifo-size = < 0x4 >;          /* in zephyr/dts/arm/nxp/nxp_ke1xf.dtsi:403 */
			status = "okay";                 /* in zephyr/boards/nxp/twr_ke18f/twr_ke18f.dts:288 */
			pinctrl-0 = < &lpspi1_default >; /* in zephyr/boards/nxp/twr_ke18f/twr_ke18f.dts:289 */
			pinctrl-names = "default";       /* in zephyr/boards/nxp/twr_ke18f/twr_ke18f.dts:290 */
		};

		/* node '/soc/can@40024000' defined in zephyr/dts/arm/nxp/nxp_ke1xf.dtsi:406 */
		flexcan0: can@40024000 {
			compatible = "nxp,flexcan";        /* in zephyr/dts/arm/nxp/nxp_ke1xf.dtsi:407 */
			reg = < 0x40024000 0x1000 >;       /* in zephyr/dts/arm/nxp/nxp_ke1xf.dtsi:408 */
			interrupts = < 0x4e 0x0 >,
			             < 0x4f 0x0 >,
			             < 0x50 0x0 >,
			             < 0x51 0x0 >;         /* in zephyr/dts/arm/nxp/nxp_ke1xf.dtsi:409 */
			interrupt-names = "warning",
			                  "error",
			                  "wake-up",
			                  "mb-0-15";       /* in zephyr/dts/arm/nxp/nxp_ke1xf.dtsi:410 */
			clocks = < &scg 0x1 >;             /* in zephyr/dts/arm/nxp/nxp_ke1xf.dtsi:412 */
			clk-source = < 0x1 >;              /* in zephyr/dts/arm/nxp/nxp_ke1xf.dtsi:413 */
			status = "okay";                   /* in zephyr/boards/nxp/twr_ke18f/twr_ke18f.dts:312 */
			pinctrl-0 = < &flexcan0_default >; /* in zephyr/boards/nxp/twr_ke18f/twr_ke18f.dts:313 */
			pinctrl-names = "default";         /* in zephyr/boards/nxp/twr_ke18f/twr_ke18f.dts:314 */

			/* node '/soc/can@40024000/can-transceiver' defined in zephyr/boards/nxp/twr_ke18f/twr_ke18f.dts:316 */
			can-transceiver {
				max-bitrate = < 0xf4240 >; /* in zephyr/boards/nxp/twr_ke18f/twr_ke18f.dts:317 */
			};
		};

		/* node '/soc/can@40025000' defined in zephyr/dts/arm/nxp/nxp_ke1xf.dtsi:417 */
		flexcan1: can@40025000 {
			compatible = "nxp,flexcan";  /* in zephyr/dts/arm/nxp/nxp_ke1xf.dtsi:418 */
			reg = < 0x40025000 0x1000 >; /* in zephyr/dts/arm/nxp/nxp_ke1xf.dtsi:419 */
			interrupts = < 0x55 0x0 >,
			             < 0x56 0x0 >,
			             < 0x57 0x0 >,
			             < 0x58 0x0 >;   /* in zephyr/dts/arm/nxp/nxp_ke1xf.dtsi:420 */
			interrupt-names = "warning",
			                  "error",
			                  "wake-up",
			                  "mb-0-15"; /* in zephyr/dts/arm/nxp/nxp_ke1xf.dtsi:421 */
			clocks = < &scg 0x1 >;       /* in zephyr/dts/arm/nxp/nxp_ke1xf.dtsi:423 */
			clk-source = < 0x1 >;        /* in zephyr/dts/arm/nxp/nxp_ke1xf.dtsi:424 */
			status = "disabled";         /* in zephyr/dts/arm/nxp/nxp_ke1xf.dtsi:425 */
		};

		/* node '/soc/pinmux@40049000' defined in zephyr/dts/arm/nxp/nxp_ke1xf.dtsi:428 */
		porta: pinmux@40049000 {
			compatible = "nxp,port-pinmux"; /* in zephyr/dts/arm/nxp/nxp_ke1xf.dtsi:429 */
			reg = < 0x40049000 0x1000 >;    /* in zephyr/dts/arm/nxp/nxp_ke1xf.dtsi:430 */
			clocks = < &pcc 0x124 0x0 >;    /* in zephyr/dts/arm/nxp/nxp_ke1xf.dtsi:431 */
			phandle = < 0x16 >;             /* in zephyr/dts/arm/nxp/nxp_ke1xf.dtsi:465 */
		};

		/* node '/soc/pinmux@4004a000' defined in zephyr/dts/arm/nxp/nxp_ke1xf.dtsi:434 */
		portb: pinmux@4004a000 {
			compatible = "nxp,port-pinmux"; /* in zephyr/dts/arm/nxp/nxp_ke1xf.dtsi:435 */
			reg = < 0x4004a000 0x1000 >;    /* in zephyr/dts/arm/nxp/nxp_ke1xf.dtsi:436 */
			clocks = < &pcc 0x128 0x0 >;    /* in zephyr/dts/arm/nxp/nxp_ke1xf.dtsi:437 */
			phandle = < 0x17 >;             /* in zephyr/dts/arm/nxp/nxp_ke1xf.dtsi:475 */
		};

		/* node '/soc/pinmux@4004b000' defined in zephyr/dts/arm/nxp/nxp_ke1xf.dtsi:440 */
		portc: pinmux@4004b000 {
			compatible = "nxp,port-pinmux"; /* in zephyr/dts/arm/nxp/nxp_ke1xf.dtsi:441 */
			reg = < 0x4004b000 0x1000 >;    /* in zephyr/dts/arm/nxp/nxp_ke1xf.dtsi:442 */
			clocks = < &pcc 0x12c 0x0 >;    /* in zephyr/dts/arm/nxp/nxp_ke1xf.dtsi:443 */
			phandle = < 0x18 >;             /* in zephyr/dts/arm/nxp/nxp_ke1xf.dtsi:485 */
		};

		/* node '/soc/pinmux@4004c000' defined in zephyr/dts/arm/nxp/nxp_ke1xf.dtsi:446 */
		portd: pinmux@4004c000 {
			compatible = "nxp,port-pinmux"; /* in zephyr/dts/arm/nxp/nxp_ke1xf.dtsi:447 */
			reg = < 0x4004c000 0x1000 >;    /* in zephyr/dts/arm/nxp/nxp_ke1xf.dtsi:448 */
			clocks = < &pcc 0x130 0x0 >;    /* in zephyr/dts/arm/nxp/nxp_ke1xf.dtsi:449 */
			phandle = < 0x19 >;             /* in zephyr/dts/arm/nxp/nxp_ke1xf.dtsi:495 */
		};

		/* node '/soc/pinmux@4004d000' defined in zephyr/dts/arm/nxp/nxp_ke1xf.dtsi:452 */
		porte: pinmux@4004d000 {
			compatible = "nxp,port-pinmux"; /* in zephyr/dts/arm/nxp/nxp_ke1xf.dtsi:453 */
			reg = < 0x4004d000 0x1000 >;    /* in zephyr/dts/arm/nxp/nxp_ke1xf.dtsi:454 */
			clocks = < &pcc 0x134 0x0 >;    /* in zephyr/dts/arm/nxp/nxp_ke1xf.dtsi:455 */
			phandle = < 0x1a >;             /* in zephyr/dts/arm/nxp/nxp_ke1xf.dtsi:505 */
		};

		/* node '/soc/gpio@400ff000' defined in zephyr/dts/arm/nxp/nxp_ke1xf.dtsi:458 */
		gpioa: gpio@400ff000 {
			compatible = "nxp,kinetis-gpio"; /* in zephyr/dts/arm/nxp/nxp_ke1xf.dtsi:459 */
			reg = < 0x400ff000 0x40 >;       /* in zephyr/dts/arm/nxp/nxp_ke1xf.dtsi:461 */
			interrupts = < 0x3b 0x2 >;       /* in zephyr/dts/arm/nxp/nxp_ke1xf.dtsi:462 */
			gpio-controller;                 /* in zephyr/dts/arm/nxp/nxp_ke1xf.dtsi:463 */
			#gpio-cells = < 0x2 >;           /* in zephyr/dts/arm/nxp/nxp_ke1xf.dtsi:464 */
			nxp,kinetis-port = < &porta >;   /* in zephyr/dts/arm/nxp/nxp_ke1xf.dtsi:465 */
			status = "okay";                 /* in zephyr/boards/nxp/twr_ke18f/twr_ke18f.dts:322 */
			phandle = < 0xf >;               /* in zephyr/boards/nxp/twr_ke18f/twr_ke18f.dts:261 */
		};

		/* node '/soc/gpio@400ff040' defined in zephyr/dts/arm/nxp/nxp_ke1xf.dtsi:468 */
		gpiob: gpio@400ff040 {
			compatible = "nxp,kinetis-gpio"; /* in zephyr/dts/arm/nxp/nxp_ke1xf.dtsi:469 */
			reg = < 0x400ff040 0x40 >;       /* in zephyr/dts/arm/nxp/nxp_ke1xf.dtsi:471 */
			interrupts = < 0x3c 0x2 >;       /* in zephyr/dts/arm/nxp/nxp_ke1xf.dtsi:472 */
			gpio-controller;                 /* in zephyr/dts/arm/nxp/nxp_ke1xf.dtsi:473 */
			#gpio-cells = < 0x2 >;           /* in zephyr/dts/arm/nxp/nxp_ke1xf.dtsi:474 */
			nxp,kinetis-port = < &portb >;   /* in zephyr/dts/arm/nxp/nxp_ke1xf.dtsi:475 */
			status = "okay";                 /* in zephyr/boards/nxp/twr_ke18f/twr_ke18f.dts:326 */
			phandle = < 0x25 >;              /* in zephyr/boards/nxp/twr_ke18f/twr_ke18f.dts:92 */
		};

		/* node '/soc/gpio@400ff080' defined in zephyr/dts/arm/nxp/nxp_ke1xf.dtsi:478 */
		gpioc: gpio@400ff080 {
			compatible = "nxp,kinetis-gpio"; /* in zephyr/dts/arm/nxp/nxp_ke1xf.dtsi:479 */
			reg = < 0x400ff080 0x40 >;       /* in zephyr/dts/arm/nxp/nxp_ke1xf.dtsi:481 */
			interrupts = < 0x3d 0x2 >;       /* in zephyr/dts/arm/nxp/nxp_ke1xf.dtsi:482 */
			gpio-controller;                 /* in zephyr/dts/arm/nxp/nxp_ke1xf.dtsi:483 */
			#gpio-cells = < 0x2 >;           /* in zephyr/dts/arm/nxp/nxp_ke1xf.dtsi:484 */
			nxp,kinetis-port = < &portc >;   /* in zephyr/dts/arm/nxp/nxp_ke1xf.dtsi:485 */
			status = "okay";                 /* in zephyr/boards/nxp/twr_ke18f/twr_ke18f.dts:330 */
			phandle = < 0x10 >;              /* in zephyr/boards/nxp/twr_ke18f/twr_ke18f.dts:267 */
		};

		/* node '/soc/gpio@400ff0c0' defined in zephyr/dts/arm/nxp/nxp_ke1xf.dtsi:488 */
		gpiod: gpio@400ff0c0 {
			compatible = "nxp,kinetis-gpio"; /* in zephyr/dts/arm/nxp/nxp_ke1xf.dtsi:489 */
			reg = < 0x400ff0c0 0x40 >;       /* in zephyr/dts/arm/nxp/nxp_ke1xf.dtsi:491 */
			interrupts = < 0x3e 0x2 >;       /* in zephyr/dts/arm/nxp/nxp_ke1xf.dtsi:492 */
			gpio-controller;                 /* in zephyr/dts/arm/nxp/nxp_ke1xf.dtsi:493 */
			#gpio-cells = < 0x2 >;           /* in zephyr/dts/arm/nxp/nxp_ke1xf.dtsi:494 */
			nxp,kinetis-port = < &portd >;   /* in zephyr/dts/arm/nxp/nxp_ke1xf.dtsi:495 */
			status = "okay";                 /* in zephyr/boards/nxp/twr_ke18f/twr_ke18f.dts:334 */
			phandle = < 0x12 >;              /* in zephyr/boards/nxp/twr_ke18f/twr_ke18f.dts:275 */
		};

		/* node '/soc/gpio@400ff100' defined in zephyr/dts/arm/nxp/nxp_ke1xf.dtsi:498 */
		gpioe: gpio@400ff100 {
			compatible = "nxp,kinetis-gpio"; /* in zephyr/dts/arm/nxp/nxp_ke1xf.dtsi:499 */
			reg = < 0x400ff100 0x40 >;       /* in zephyr/dts/arm/nxp/nxp_ke1xf.dtsi:501 */
			interrupts = < 0x3f 0x2 >;       /* in zephyr/dts/arm/nxp/nxp_ke1xf.dtsi:502 */
			gpio-controller;                 /* in zephyr/dts/arm/nxp/nxp_ke1xf.dtsi:503 */
			#gpio-cells = < 0x2 >;           /* in zephyr/dts/arm/nxp/nxp_ke1xf.dtsi:504 */
			nxp,kinetis-port = < &porte >;   /* in zephyr/dts/arm/nxp/nxp_ke1xf.dtsi:505 */
			status = "okay";                 /* in zephyr/boards/nxp/twr_ke18f/twr_ke18f.dts:338 */
		};

		/* node '/soc/adc@4003b000' defined in zephyr/dts/arm/nxp/nxp_ke1xf.dtsi:508 */
		adc0: adc@4003b000 {
			compatible = "nxp,adc12";      /* in zephyr/dts/arm/nxp/nxp_ke1xf.dtsi:509 */
			reg = < 0x4003b000 0x1000 >;   /* in zephyr/dts/arm/nxp/nxp_ke1xf.dtsi:510 */
			interrupts = < 0x27 0x0 >;     /* in zephyr/dts/arm/nxp/nxp_ke1xf.dtsi:511 */
			clocks = < &pcc 0xec 0x3 >;    /* in zephyr/dts/arm/nxp/nxp_ke1xf.dtsi:512 */
			clk-source = < 0x0 >;          /* in zephyr/dts/arm/nxp/nxp_ke1xf.dtsi:513 */
			clk-divider = < 0x1 >;         /* in zephyr/dts/arm/nxp/nxp_ke1xf.dtsi:514 */
			#io-channel-cells = < 0x1 >;   /* in zephyr/dts/arm/nxp/nxp_ke1xf.dtsi:516 */
			status = "okay";               /* in zephyr/boards/nxp/twr_ke18f/twr_ke18f.dts:300 */
			sample-time = < 0xc >;         /* in zephyr/boards/nxp/twr_ke18f/twr_ke18f.dts:301 */
			vref-mv = < 0xce4 >;           /* in zephyr/boards/nxp/twr_ke18f/twr_ke18f.dts:302 */
			pinctrl-0 = < &adc0_default >; /* in zephyr/boards/nxp/twr_ke18f/twr_ke18f.dts:303 */
			pinctrl-names = "default";     /* in zephyr/boards/nxp/twr_ke18f/twr_ke18f.dts:304 */
			phandle = < 0x22 >;            /* in zephyr/dts/arm/nxp/nxp_ke1xf.dtsi:62 */
		};

		/* node '/soc/adc@40027000' defined in zephyr/dts/arm/nxp/nxp_ke1xf.dtsi:519 */
		adc1: adc@40027000 {
			compatible = "nxp,adc12";    /* in zephyr/dts/arm/nxp/nxp_ke1xf.dtsi:520 */
			reg = < 0x40027000 0x1000 >; /* in zephyr/dts/arm/nxp/nxp_ke1xf.dtsi:521 */
			interrupts = < 0x49 0x0 >;   /* in zephyr/dts/arm/nxp/nxp_ke1xf.dtsi:522 */
			clocks = < &pcc 0x9c 0x3 >;  /* in zephyr/dts/arm/nxp/nxp_ke1xf.dtsi:523 */
			clk-source = < 0x0 >;        /* in zephyr/dts/arm/nxp/nxp_ke1xf.dtsi:524 */
			clk-divider = < 0x1 >;       /* in zephyr/dts/arm/nxp/nxp_ke1xf.dtsi:525 */
			status = "disabled";         /* in zephyr/dts/arm/nxp/nxp_ke1xf.dtsi:526 */
			#io-channel-cells = < 0x1 >; /* in zephyr/dts/arm/nxp/nxp_ke1xf.dtsi:527 */
			phandle = < 0x23 >;          /* in zephyr/dts/arm/nxp/nxp_ke1xf.dtsi:73 */
		};

		/* node '/soc/adc@4003c000' defined in zephyr/dts/arm/nxp/nxp_ke1xf.dtsi:530 */
		adc2: adc@4003c000 {
			compatible = "nxp,adc12";    /* in zephyr/dts/arm/nxp/nxp_ke1xf.dtsi:531 */
			reg = < 0x4003c000 0x1000 >; /* in zephyr/dts/arm/nxp/nxp_ke1xf.dtsi:532 */
			interrupts = < 0x4a 0x0 >;   /* in zephyr/dts/arm/nxp/nxp_ke1xf.dtsi:533 */
			clocks = < &pcc 0xf0 0x3 >;  /* in zephyr/dts/arm/nxp/nxp_ke1xf.dtsi:534 */
			clk-source = < 0x0 >;        /* in zephyr/dts/arm/nxp/nxp_ke1xf.dtsi:535 */
			clk-divider = < 0x1 >;       /* in zephyr/dts/arm/nxp/nxp_ke1xf.dtsi:536 */
			status = "disabled";         /* in zephyr/dts/arm/nxp/nxp_ke1xf.dtsi:537 */
			#io-channel-cells = < 0x1 >; /* in zephyr/dts/arm/nxp/nxp_ke1xf.dtsi:538 */
			phandle = < 0x24 >;          /* in zephyr/dts/arm/nxp/nxp_ke1xf.dtsi:84 */
		};

		/* node '/soc/ftm@40038000' defined in zephyr/dts/arm/nxp/nxp_ke1xf.dtsi:541 */
		ftm0: ftm@40038000 {
			reg = < 0x40038000 0x1000 >;   /* in zephyr/dts/arm/nxp/nxp_ke1xf.dtsi:543 */
			interrupts = < 0x2a 0x0 >;     /* in zephyr/dts/arm/nxp/nxp_ke1xf.dtsi:544 */
			clocks = < &pcc 0xe0 0x3 >;    /* in zephyr/dts/arm/nxp/nxp_ke1xf.dtsi:545 */
			prescaler = < 0x10 >;          /* in zephyr/dts/arm/nxp/nxp_ke1xf.dtsi:546 */
			status = "okay";               /* in zephyr/boards/nxp/twr_ke18f/twr_ke18f.dts:240 */
			compatible = "nxp,ftm-pwm";    /* in zephyr/boards/nxp/twr_ke18f/twr_ke18f.dts:241 */
			#pwm-cells = < 0x3 >;          /* in zephyr/boards/nxp/twr_ke18f/twr_ke18f.dts:242 */
			pinctrl-0 = < &ftm0_default >; /* in zephyr/boards/nxp/twr_ke18f/twr_ke18f.dts:243 */
			pinctrl-names = "default";     /* in zephyr/boards/nxp/twr_ke18f/twr_ke18f.dts:244 */
			clock-source = "fixed";        /* in zephyr/boards/nxp/twr_ke18f/twr_ke18f.dts:245 */
			phandle = < 0x27 >;            /* in zephyr/boards/nxp/twr_ke18f/twr_ke18f.dts:121 */
		};

		/* node '/soc/ftm@40039000' defined in zephyr/dts/arm/nxp/nxp_ke1xf.dtsi:550 */
		ftm1: ftm@40039000 {
			compatible = "nxp,ftm";      /* in zephyr/dts/arm/nxp/nxp_ke1xf.dtsi:551 */
			reg = < 0x40039000 0x1000 >; /* in zephyr/dts/arm/nxp/nxp_ke1xf.dtsi:552 */
			interrupts = < 0x2b 0x0 >;   /* in zephyr/dts/arm/nxp/nxp_ke1xf.dtsi:553 */
			clocks = < &pcc 0xe4 0x3 >;  /* in zephyr/dts/arm/nxp/nxp_ke1xf.dtsi:554 */
			prescaler = < 0x10 >;        /* in zephyr/dts/arm/nxp/nxp_ke1xf.dtsi:555 */
			status = "disabled";         /* in zephyr/dts/arm/nxp/nxp_ke1xf.dtsi:556 */
		};

		/* node '/soc/ftm@4003a000' defined in zephyr/dts/arm/nxp/nxp_ke1xf.dtsi:559 */
		ftm2: ftm@4003a000 {
			compatible = "nxp,ftm";      /* in zephyr/dts/arm/nxp/nxp_ke1xf.dtsi:560 */
			reg = < 0x4003a000 0x1000 >; /* in zephyr/dts/arm/nxp/nxp_ke1xf.dtsi:561 */
			interrupts = < 0x2c 0x0 >;   /* in zephyr/dts/arm/nxp/nxp_ke1xf.dtsi:562 */
			clocks = < &pcc 0xe8 0x3 >;  /* in zephyr/dts/arm/nxp/nxp_ke1xf.dtsi:563 */
			prescaler = < 0x10 >;        /* in zephyr/dts/arm/nxp/nxp_ke1xf.dtsi:564 */
			status = "disabled";         /* in zephyr/dts/arm/nxp/nxp_ke1xf.dtsi:565 */
		};

		/* node '/soc/ftm@40026000' defined in zephyr/dts/arm/nxp/nxp_ke1xf.dtsi:568 */
		ftm3: ftm@40026000 {
			reg = < 0x40026000 0x1000 >;   /* in zephyr/dts/arm/nxp/nxp_ke1xf.dtsi:570 */
			interrupts = < 0x47 0x0 >;     /* in zephyr/dts/arm/nxp/nxp_ke1xf.dtsi:571 */
			clocks = < &pcc 0x98 0x3 >;    /* in zephyr/dts/arm/nxp/nxp_ke1xf.dtsi:572 */
			prescaler = < 0x10 >;          /* in zephyr/dts/arm/nxp/nxp_ke1xf.dtsi:573 */
			status = "okay";               /* in zephyr/boards/nxp/twr_ke18f/twr_ke18f.dts:249 */
			compatible = "nxp,ftm-pwm";    /* in zephyr/boards/nxp/twr_ke18f/twr_ke18f.dts:250 */
			#pwm-cells = < 0x3 >;          /* in zephyr/boards/nxp/twr_ke18f/twr_ke18f.dts:251 */
			pinctrl-0 = < &ftm3_default >; /* in zephyr/boards/nxp/twr_ke18f/twr_ke18f.dts:252 */
			pinctrl-names = "default";     /* in zephyr/boards/nxp/twr_ke18f/twr_ke18f.dts:253 */
			clock-source = "fixed";        /* in zephyr/boards/nxp/twr_ke18f/twr_ke18f.dts:254 */
			phandle = < 0x26 >;            /* in zephyr/boards/nxp/twr_ke18f/twr_ke18f.dts:101 */
		};

		/* node '/soc/cmp@40073000' defined in zephyr/dts/arm/nxp/nxp_ke1xf.dtsi:577 */
		cmp0: cmp@40073000 {
			compatible = "nxp,kinetis-acmp"; /* in zephyr/dts/arm/nxp/nxp_ke1xf.dtsi:578 */
			reg = < 0x40073000 0x1000 >;     /* in zephyr/dts/arm/nxp/nxp_ke1xf.dtsi:579 */
			interrupts = < 0x28 0x0 >;       /* in zephyr/dts/arm/nxp/nxp_ke1xf.dtsi:580 */
			clocks = < &scg 0x1 >;           /* in zephyr/dts/arm/nxp/nxp_ke1xf.dtsi:581 */
			status = "disabled";             /* in zephyr/dts/arm/nxp/nxp_ke1xf.dtsi:582 */
		};

		/* node '/soc/cmp@40074000' defined in zephyr/dts/arm/nxp/nxp_ke1xf.dtsi:585 */
		cmp1: cmp@40074000 {
			compatible = "nxp,kinetis-acmp"; /* in zephyr/dts/arm/nxp/nxp_ke1xf.dtsi:586 */
			reg = < 0x40074000 0x1000 >;     /* in zephyr/dts/arm/nxp/nxp_ke1xf.dtsi:587 */
			interrupts = < 0x29 0x0 >;       /* in zephyr/dts/arm/nxp/nxp_ke1xf.dtsi:588 */
			clocks = < &scg 0x1 >;           /* in zephyr/dts/arm/nxp/nxp_ke1xf.dtsi:589 */
			status = "disabled";             /* in zephyr/dts/arm/nxp/nxp_ke1xf.dtsi:590 */
		};

		/* node '/soc/cmp@40075000' defined in zephyr/dts/arm/nxp/nxp_ke1xf.dtsi:593 */
		cmp2: cmp@40075000 {
			compatible = "nxp,kinetis-acmp"; /* in zephyr/dts/arm/nxp/nxp_ke1xf.dtsi:594 */
			reg = < 0x40075000 0x1000 >;     /* in zephyr/dts/arm/nxp/nxp_ke1xf.dtsi:595 */
			interrupts = < 0x46 0x0 >;       /* in zephyr/dts/arm/nxp/nxp_ke1xf.dtsi:596 */
			clocks = < &scg 0x1 >;           /* in zephyr/dts/arm/nxp/nxp_ke1xf.dtsi:597 */
			status = "disabled";             /* in zephyr/dts/arm/nxp/nxp_ke1xf.dtsi:598 */
		};

		/* node '/soc/flexio@4005a000' defined in zephyr/dts/arm/nxp/nxp_ke1xf.dtsi:601 */
		flexio1: flexio@4005a000 {
			compatible = "nxp,flexio";   /* in zephyr/dts/arm/nxp/nxp_ke1xf.dtsi:602 */
			reg = < 0x4005a000 0x1000 >; /* in zephyr/dts/arm/nxp/nxp_ke1xf.dtsi:603 */
			interrupts = < 0x45 0x0 >;   /* in zephyr/dts/arm/nxp/nxp_ke1xf.dtsi:605 */
			clocks = < &pcc 0x168 0x3 >; /* in zephyr/dts/arm/nxp/nxp_ke1xf.dtsi:606 */
			status = "okay";             /* in zephyr/boards/nxp/twr_ke18f/twr_ke18f.dts:346 */
		};
	};

	/* node '/cpus' defined in zephyr/dts/arm/nxp/nxp_ke1xf.dtsi:23 */
	cpus {
		#address-cells = < 0x1 >; /* in zephyr/dts/arm/nxp/nxp_ke1xf.dtsi:24 */
		#size-cells = < 0x0 >;    /* in zephyr/dts/arm/nxp/nxp_ke1xf.dtsi:25 */

		/* node '/cpus/cpu@0' defined in zephyr/dts/arm/nxp/nxp_ke1xf.dtsi:27 */
		cpu0: cpu@0 {
			device_type = "cpu";                                /* in zephyr/dts/arm/nxp/nxp_ke1xf.dtsi:28 */
			compatible = "arm,cortex-m4f";                      /* in zephyr/dts/arm/nxp/nxp_ke1xf.dtsi:29 */
			reg = < 0x0 >;                                      /* in zephyr/dts/arm/nxp/nxp_ke1xf.dtsi:30 */
			cpu-power-states = < &idle &stop &pstop1 &pstop2 >; /* in zephyr/dts/arm/nxp/nxp_ke1xf.dtsi:31 */
			clock-frequency = < 0x7270e00 >;                    /* in zephyr/boards/nxp/twr_ke18f/twr_ke18f.dts:154 */
		};

		/* node '/cpus/power-states' defined in zephyr/dts/arm/nxp/nxp_ke1xf.dtsi:34 */
		power-states {

			/* node '/cpus/power-states/idle' defined in zephyr/dts/arm/nxp/nxp_ke1xf.dtsi:35 */
			idle: idle {
				compatible = "zephyr,power-state"; /* in zephyr/dts/arm/nxp/nxp_ke1xf.dtsi:36 */
				power-state-name = "runtime-idle"; /* in zephyr/dts/arm/nxp/nxp_ke1xf.dtsi:37 */
				min-residency-us = < 0x1 >;        /* in zephyr/boards/nxp/twr_ke18f/twr_ke18f.dts:158 */
				phandle = < 0x1e >;                /* in zephyr/dts/arm/nxp/nxp_ke1xf.dtsi:31 */
			};

			/* node '/cpus/power-states/stop' defined in zephyr/dts/arm/nxp/nxp_ke1xf.dtsi:40 */
			stop: stop {
				compatible = "zephyr,power-state";    /* in zephyr/dts/arm/nxp/nxp_ke1xf.dtsi:41 */
				power-state-name = "suspend-to-idle"; /* in zephyr/dts/arm/nxp/nxp_ke1xf.dtsi:42 */
				substate-id = < 0x0 >;                /* in zephyr/dts/arm/nxp/nxp_ke1xf.dtsi:43 */
				min-residency-us = < 0x4e20 >;        /* in zephyr/boards/nxp/twr_ke18f/twr_ke18f.dts:162 */
				exit-latency-us = < 0xd >;            /* in zephyr/boards/nxp/twr_ke18f/twr_ke18f.dts:163 */
				phandle = < 0x1f >;                   /* in zephyr/dts/arm/nxp/nxp_ke1xf.dtsi:31 */
			};

			/* node '/cpus/power-states/pstop1' defined in zephyr/dts/arm/nxp/nxp_ke1xf.dtsi:46 */
			pstop1: pstop1 {
				compatible = "zephyr,power-state";    /* in zephyr/dts/arm/nxp/nxp_ke1xf.dtsi:47 */
				power-state-name = "suspend-to-idle"; /* in zephyr/dts/arm/nxp/nxp_ke1xf.dtsi:48 */
				substate-id = < 0x1 >;                /* in zephyr/dts/arm/nxp/nxp_ke1xf.dtsi:49 */
				phandle = < 0x20 >;                   /* in zephyr/dts/arm/nxp/nxp_ke1xf.dtsi:31 */
			};

			/* node '/cpus/power-states/pstop2' defined in zephyr/dts/arm/nxp/nxp_ke1xf.dtsi:52 */
			pstop2: pstop2 {
				compatible = "zephyr,power-state";    /* in zephyr/dts/arm/nxp/nxp_ke1xf.dtsi:53 */
				power-state-name = "suspend-to-idle"; /* in zephyr/dts/arm/nxp/nxp_ke1xf.dtsi:54 */
				substate-id = < 0x2 >;                /* in zephyr/dts/arm/nxp/nxp_ke1xf.dtsi:55 */
				phandle = < 0x21 >;                   /* in zephyr/dts/arm/nxp/nxp_ke1xf.dtsi:31 */
			};
		};
	};

	/* node '/temp0' defined in zephyr/dts/arm/nxp/nxp_ke1xf.dtsi:60 */
	temp0: temp0 {
		compatible = "nxp,kinetis-temperature"; /* in zephyr/dts/arm/nxp/nxp_ke1xf.dtsi:61 */
		io-channels = < &adc0 0x1a >,
		              < &adc0 0x1b >;           /* in zephyr/dts/arm/nxp/nxp_ke1xf.dtsi:62 */
		io-channel-names = "SENSOR",
		                   "BANDGAP";           /* in zephyr/dts/arm/nxp/nxp_ke1xf.dtsi:63 */
		bandgap-voltage = < 0xf4240 >;          /* in zephyr/dts/arm/nxp/nxp_ke1xf.dtsi:64 */
		vtemp25 = < 0xb4c94 >;                  /* in zephyr/dts/arm/nxp/nxp_ke1xf.dtsi:65 */
		sensor-slope-cold = < 0x61c >;          /* in zephyr/dts/arm/nxp/nxp_ke1xf.dtsi:66 */
		sensor-slope-hot = < 0x61c >;           /* in zephyr/dts/arm/nxp/nxp_ke1xf.dtsi:67 */
		status = "okay";                        /* in zephyr/boards/nxp/twr_ke18f/twr_ke18f.dts:308 */
	};

	/* node '/temp1' defined in zephyr/dts/arm/nxp/nxp_ke1xf.dtsi:71 */
	temp1: temp1 {
		compatible = "nxp,kinetis-temperature"; /* in zephyr/dts/arm/nxp/nxp_ke1xf.dtsi:72 */
		io-channels = < &adc1 0x1a >,
		              < &adc1 0x1b >;           /* in zephyr/dts/arm/nxp/nxp_ke1xf.dtsi:73 */
		io-channel-names = "SENSOR",
		                   "BANDGAP";           /* in zephyr/dts/arm/nxp/nxp_ke1xf.dtsi:74 */
		bandgap-voltage = < 0xf4240 >;          /* in zephyr/dts/arm/nxp/nxp_ke1xf.dtsi:75 */
		vtemp25 = < 0xb4c94 >;                  /* in zephyr/dts/arm/nxp/nxp_ke1xf.dtsi:76 */
		sensor-slope-cold = < 0x61c >;          /* in zephyr/dts/arm/nxp/nxp_ke1xf.dtsi:77 */
		sensor-slope-hot = < 0x61c >;           /* in zephyr/dts/arm/nxp/nxp_ke1xf.dtsi:78 */
		status = "disabled";                    /* in zephyr/dts/arm/nxp/nxp_ke1xf.dtsi:79 */
	};

	/* node '/temp2' defined in zephyr/dts/arm/nxp/nxp_ke1xf.dtsi:82 */
	temp2: temp2 {
		compatible = "nxp,kinetis-temperature"; /* in zephyr/dts/arm/nxp/nxp_ke1xf.dtsi:83 */
		io-channels = < &adc2 0x1a >,
		              < &adc2 0x1b >;           /* in zephyr/dts/arm/nxp/nxp_ke1xf.dtsi:84 */
		io-channel-names = "SENSOR",
		                   "BANDGAP";           /* in zephyr/dts/arm/nxp/nxp_ke1xf.dtsi:85 */
		bandgap-voltage = < 0xf4240 >;          /* in zephyr/dts/arm/nxp/nxp_ke1xf.dtsi:86 */
		vtemp25 = < 0xb4c94 >;                  /* in zephyr/dts/arm/nxp/nxp_ke1xf.dtsi:87 */
		sensor-slope-cold = < 0x61c >;          /* in zephyr/dts/arm/nxp/nxp_ke1xf.dtsi:88 */
		sensor-slope-hot = < 0x61c >;           /* in zephyr/dts/arm/nxp/nxp_ke1xf.dtsi:89 */
		status = "disabled";                    /* in zephyr/dts/arm/nxp/nxp_ke1xf.dtsi:90 */
	};

	/* node '/pinctrl' defined in zephyr/dts/arm/nxp/nxp_ke1xf.dtsi:94 */
	pinctrl: pinctrl {
		compatible = "nxp,port-pinctrl"; /* in zephyr/dts/arm/nxp/nxp_ke1xf.dtsi:95 */
		status = "okay";                 /* in zephyr/dts/arm/nxp/nxp_ke1xf.dtsi:96 */

		/* node '/pinctrl/adc0_default' defined in zephyr/boards/nxp/twr_ke18f/twr_ke18f-pinctrl.dtsi:12 */
		adc0_default: adc0_default {
			phandle = < 0x1b >; /* in zephyr/boards/nxp/twr_ke18f/twr_ke18f.dts:303 */

			/* node '/pinctrl/adc0_default/group0' defined in zephyr/boards/nxp/twr_ke18f/twr_ke18f-pinctrl.dtsi:13 */
			group0 {
				pinmux = < 0x0 >,
				         < 0x400000 >,
				         < 0x23800000 >; /* in zephyr/boards/nxp/twr_ke18f/twr_ke18f-pinctrl.dtsi:14 */
				drive-strength = "low";  /* in zephyr/boards/nxp/twr_ke18f/twr_ke18f-pinctrl.dtsi:17 */
				slew-rate = "slow";      /* in zephyr/boards/nxp/twr_ke18f/twr_ke18f-pinctrl.dtsi:18 */
			};
		};

		/* node '/pinctrl/dac0_default' defined in zephyr/boards/nxp/twr_ke18f/twr_ke18f-pinctrl.dtsi:22 */
		dac0_default: dac0_default {
			phandle = < 0x9 >; /* in zephyr/boards/nxp/twr_ke18f/twr_ke18f.dts:295 */

			/* node '/pinctrl/dac0_default/group0' defined in zephyr/boards/nxp/twr_ke18f/twr_ke18f-pinctrl.dtsi:23 */
			group0 {
				pinmux = < 0x42400000 >; /* in zephyr/boards/nxp/twr_ke18f/twr_ke18f-pinctrl.dtsi:24 */
				drive-strength = "low";  /* in zephyr/boards/nxp/twr_ke18f/twr_ke18f-pinctrl.dtsi:25 */
				slew-rate = "slow";      /* in zephyr/boards/nxp/twr_ke18f/twr_ke18f-pinctrl.dtsi:26 */
			};
		};

		/* node '/pinctrl/flexcan0_default' defined in zephyr/boards/nxp/twr_ke18f/twr_ke18f-pinctrl.dtsi:30 */
		flexcan0_default: flexcan0_default {
			phandle = < 0x15 >; /* in zephyr/boards/nxp/twr_ke18f/twr_ke18f.dts:313 */

			/* node '/pinctrl/flexcan0_default/group0' defined in zephyr/boards/nxp/twr_ke18f/twr_ke18f-pinctrl.dtsi:31 */
			group0 {
				pinmux = < 0x41000500 >,
				         < 0x41400500 >; /* in zephyr/boards/nxp/twr_ke18f/twr_ke18f-pinctrl.dtsi:32 */
				drive-strength = "low";  /* in zephyr/boards/nxp/twr_ke18f/twr_ke18f-pinctrl.dtsi:34 */
				slew-rate = "slow";      /* in zephyr/boards/nxp/twr_ke18f/twr_ke18f-pinctrl.dtsi:35 */
			};
		};

		/* node '/pinctrl/flexio_clockout' defined in zephyr/boards/nxp/twr_ke18f/twr_ke18f-pinctrl.dtsi:40 */
		flexio_clockout: flexio_clockout {

			/* node '/pinctrl/flexio_clockout/group0' defined in zephyr/boards/nxp/twr_ke18f/twr_ke18f-pinctrl.dtsi:41 */
			group0 {
				pinmux = < 0x42800200 >; /* in zephyr/boards/nxp/twr_ke18f/twr_ke18f-pinctrl.dtsi:42 */
				drive-strength = "low";  /* in zephyr/boards/nxp/twr_ke18f/twr_ke18f-pinctrl.dtsi:43 */
				slew-rate = "slow";      /* in zephyr/boards/nxp/twr_ke18f/twr_ke18f-pinctrl.dtsi:44 */
			};
		};

		/* node '/pinctrl/ftm0_default' defined in zephyr/boards/nxp/twr_ke18f/twr_ke18f-pinctrl.dtsi:48 */
		ftm0_default: ftm0_default {
			phandle = < 0x1c >; /* in zephyr/boards/nxp/twr_ke18f/twr_ke18f.dts:243 */

			/* node '/pinctrl/ftm0_default/group0' defined in zephyr/boards/nxp/twr_ke18f/twr_ke18f-pinctrl.dtsi:49 */
			group0 {
				pinmux = < 0x33c00200 >,
				         < 0x34000200 >,
				         < 0x11400200 >; /* in zephyr/boards/nxp/twr_ke18f/twr_ke18f-pinctrl.dtsi:50 */
				drive-strength = "low";  /* in zephyr/boards/nxp/twr_ke18f/twr_ke18f-pinctrl.dtsi:53 */
				slew-rate = "slow";      /* in zephyr/boards/nxp/twr_ke18f/twr_ke18f-pinctrl.dtsi:54 */
			};
		};

		/* node '/pinctrl/ftm3_default' defined in zephyr/boards/nxp/twr_ke18f/twr_ke18f-pinctrl.dtsi:58 */
		ftm3_default: ftm3_default {
			phandle = < 0x1d >; /* in zephyr/boards/nxp/twr_ke18f/twr_ke18f.dts:252 */

			/* node '/pinctrl/ftm3_default/group0' defined in zephyr/boards/nxp/twr_ke18f/twr_ke18f-pinctrl.dtsi:59 */
			group0 {
				pinmux = < 0x22800200 >,
				         < 0x22c00200 >,
				         < 0x23000200 >,
				         < 0x23400200 >; /* in zephyr/boards/nxp/twr_ke18f/twr_ke18f-pinctrl.dtsi:60 */
				drive-strength = "low";  /* in zephyr/boards/nxp/twr_ke18f/twr_ke18f-pinctrl.dtsi:64 */
				slew-rate = "slow";      /* in zephyr/boards/nxp/twr_ke18f/twr_ke18f-pinctrl.dtsi:65 */
			};
		};

		/* node '/pinctrl/lpi2c0_default' defined in zephyr/boards/nxp/twr_ke18f/twr_ke18f-pinctrl.dtsi:69 */
		lpi2c0_default: lpi2c0_default {
			phandle = < 0xe >; /* in zephyr/boards/nxp/twr_ke18f/twr_ke18f.dts:259 */

			/* node '/pinctrl/lpi2c0_default/group0' defined in zephyr/boards/nxp/twr_ke18f/twr_ke18f-pinctrl.dtsi:70 */
			group0 {
				pinmux = < 0xc00300 >,
				         < 0x800300 >;  /* in zephyr/boards/nxp/twr_ke18f/twr_ke18f-pinctrl.dtsi:71 */
				drive-strength = "low"; /* in zephyr/boards/nxp/twr_ke18f/twr_ke18f-pinctrl.dtsi:73 */
				slew-rate = "slow";     /* in zephyr/boards/nxp/twr_ke18f/twr_ke18f-pinctrl.dtsi:74 */
			};
		};

		/* node '/pinctrl/lpi2c1_default' defined in zephyr/boards/nxp/twr_ke18f/twr_ke18f-pinctrl.dtsi:78 */
		lpi2c1_default: lpi2c1_default {
			phandle = < 0x11 >; /* in zephyr/boards/nxp/twr_ke18f/twr_ke18f.dts:273 */

			/* node '/pinctrl/lpi2c1_default/group0' defined in zephyr/boards/nxp/twr_ke18f/twr_ke18f-pinctrl.dtsi:79 */
			group0 {
				pinmux = < 0x32400200 >,
				         < 0x32000200 >; /* in zephyr/boards/nxp/twr_ke18f/twr_ke18f-pinctrl.dtsi:80 */
				drive-strength = "low";  /* in zephyr/boards/nxp/twr_ke18f/twr_ke18f-pinctrl.dtsi:82 */
				slew-rate = "slow";      /* in zephyr/boards/nxp/twr_ke18f/twr_ke18f-pinctrl.dtsi:83 */
			};
		};

		/* node '/pinctrl/lpspi0_default' defined in zephyr/boards/nxp/twr_ke18f/twr_ke18f-pinctrl.dtsi:87 */
		lpspi0_default: lpspi0_default {
			phandle = < 0x13 >; /* in zephyr/boards/nxp/twr_ke18f/twr_ke18f.dts:283 */

			/* node '/pinctrl/lpspi0_default/group0' defined in zephyr/boards/nxp/twr_ke18f/twr_ke18f-pinctrl.dtsi:88 */
			group0 {
				pinmux = < 0x40000200 >,
				         < 0x40400200 >,
				         < 0x40800200 >; /* in zephyr/boards/nxp/twr_ke18f/twr_ke18f-pinctrl.dtsi:89 */
				drive-strength = "low";  /* in zephyr/boards/nxp/twr_ke18f/twr_ke18f-pinctrl.dtsi:92 */
				slew-rate = "slow";      /* in zephyr/boards/nxp/twr_ke18f/twr_ke18f-pinctrl.dtsi:93 */
			};
		};

		/* node '/pinctrl/lpspi0_pcs2' defined in zephyr/boards/nxp/twr_ke18f/twr_ke18f-pinctrl.dtsi:98 */
		lpspi0_pcs2: lpspi0_pcs2 {

			/* node '/pinctrl/lpspi0_pcs2/group0' defined in zephyr/boards/nxp/twr_ke18f/twr_ke18f-pinctrl.dtsi:99 */
			group0 {
				pinmux = < 0x40000200 >,
				         < 0x40400200 >,
				         < 0x40800200 >,
				         < 0x41800200 >; /* in zephyr/boards/nxp/twr_ke18f/twr_ke18f-pinctrl.dtsi:100 */
				drive-strength = "low";  /* in zephyr/boards/nxp/twr_ke18f/twr_ke18f-pinctrl.dtsi:104 */
				slew-rate = "slow";      /* in zephyr/boards/nxp/twr_ke18f/twr_ke18f-pinctrl.dtsi:105 */
			};
		};

		/* node '/pinctrl/lpspi1_default' defined in zephyr/boards/nxp/twr_ke18f/twr_ke18f-pinctrl.dtsi:109 */
		lpspi1_default: lpspi1_default {
			phandle = < 0x14 >; /* in zephyr/boards/nxp/twr_ke18f/twr_ke18f.dts:289 */

			/* node '/pinctrl/lpspi1_default/group0' defined in zephyr/boards/nxp/twr_ke18f/twr_ke18f-pinctrl.dtsi:110 */
			group0 {
				pinmux = < 0x30000300 >,
				         < 0x30400300 >,
				         < 0x30800300 >; /* in zephyr/boards/nxp/twr_ke18f/twr_ke18f-pinctrl.dtsi:111 */
				drive-strength = "low";  /* in zephyr/boards/nxp/twr_ke18f/twr_ke18f-pinctrl.dtsi:114 */
				slew-rate = "slow";      /* in zephyr/boards/nxp/twr_ke18f/twr_ke18f-pinctrl.dtsi:115 */
			};
		};

		/* node '/pinctrl/lpspi1_pcs0' defined in zephyr/boards/nxp/twr_ke18f/twr_ke18f-pinctrl.dtsi:120 */
		lpspi1_pcs0: lpspi1_pcs0 {

			/* node '/pinctrl/lpspi1_pcs0/group0' defined in zephyr/boards/nxp/twr_ke18f/twr_ke18f-pinctrl.dtsi:121 */
			group0 {
				pinmux = < 0x30000300 >,
				         < 0x30400300 >,
				         < 0x30800300 >,
				         < 0x30c00300 >; /* in zephyr/boards/nxp/twr_ke18f/twr_ke18f-pinctrl.dtsi:122 */
				drive-strength = "low";  /* in zephyr/boards/nxp/twr_ke18f/twr_ke18f-pinctrl.dtsi:126 */
				slew-rate = "slow";      /* in zephyr/boards/nxp/twr_ke18f/twr_ke18f-pinctrl.dtsi:127 */
			};
		};

		/* node '/pinctrl/lpspi1_pcs0_pcs2' defined in zephyr/boards/nxp/twr_ke18f/twr_ke18f-pinctrl.dtsi:132 */
		lpspi1_pcs0_pcs2: lpspi1_pcs0_pcs2 {

			/* node '/pinctrl/lpspi1_pcs0_pcs2/group0' defined in zephyr/boards/nxp/twr_ke18f/twr_ke18f-pinctrl.dtsi:133 */
			group0 {
				pinmux = < 0x30000300 >,
				         < 0x30400300 >,
				         < 0x30800300 >,
				         < 0x4000300 >,
				         < 0x30c00300 >; /* in zephyr/boards/nxp/twr_ke18f/twr_ke18f-pinctrl.dtsi:134 */
				drive-strength = "low";  /* in zephyr/boards/nxp/twr_ke18f/twr_ke18f-pinctrl.dtsi:139 */
				slew-rate = "slow";      /* in zephyr/boards/nxp/twr_ke18f/twr_ke18f-pinctrl.dtsi:140 */
			};
		};

		/* node '/pinctrl/lpspi1_pcs2' defined in zephyr/boards/nxp/twr_ke18f/twr_ke18f-pinctrl.dtsi:145 */
		lpspi1_pcs2: lpspi1_pcs2 {

			/* node '/pinctrl/lpspi1_pcs2/group0' defined in zephyr/boards/nxp/twr_ke18f/twr_ke18f-pinctrl.dtsi:146 */
			group0 {
				pinmux = < 0x30000300 >,
				         < 0x30400300 >,
				         < 0x30800300 >,
				         < 0x4000300 >;  /* in zephyr/boards/nxp/twr_ke18f/twr_ke18f-pinctrl.dtsi:147 */
				drive-strength = "low";  /* in zephyr/boards/nxp/twr_ke18f/twr_ke18f-pinctrl.dtsi:151 */
				slew-rate = "slow";      /* in zephyr/boards/nxp/twr_ke18f/twr_ke18f-pinctrl.dtsi:152 */
			};
		};

		/* node '/pinctrl/lpuart0_default' defined in zephyr/boards/nxp/twr_ke18f/twr_ke18f-pinctrl.dtsi:156 */
		lpuart0_default: lpuart0_default {
			phandle = < 0xd >; /* in zephyr/boards/nxp/twr_ke18f/twr_ke18f.dts:235 */

			/* node '/pinctrl/lpuart0_default/group0' defined in zephyr/boards/nxp/twr_ke18f/twr_ke18f-pinctrl.dtsi:157 */
			group0 {
				pinmux = < 0x10000200 >,
				         < 0x10400200 >; /* in zephyr/boards/nxp/twr_ke18f/twr_ke18f-pinctrl.dtsi:158 */
				drive-strength = "low";  /* in zephyr/boards/nxp/twr_ke18f/twr_ke18f-pinctrl.dtsi:160 */
				slew-rate = "slow";      /* in zephyr/boards/nxp/twr_ke18f/twr_ke18f-pinctrl.dtsi:161 */
			};
		};
	};

	/* node '/memory@1fff8000' defined in zephyr/dts/arm/nxp/nxp_ke1xf512vlx16.dtsi:21 */
	sram_l: memory@1fff8000 {
		compatible = "zephyr,memory-region",
		             "mmio-sram";            /* in zephyr/dts/arm/nxp/nxp_ke1xf512vlx16.dtsi:22 */
		reg = < 0x1fff8000 0x8000 >;         /* in zephyr/dts/arm/nxp/nxp_ke1xf512vlx16.dtsi:23 */
		zephyr,memory-region = "SRAML";      /* in zephyr/dts/arm/nxp/nxp_ke1xf512vlx16.dtsi:24 */
	};

	/* node '/memory@20000000' defined in zephyr/dts/arm/nxp/nxp_ke1xf512vlx16.dtsi:27 */
	sram0: memory@20000000 {
		compatible = "mmio-sram";    /* in zephyr/dts/arm/nxp/nxp_ke1xf512vlx16.dtsi:28 */
		reg = < 0x20000000 0x8000 >; /* in zephyr/dts/arm/nxp/nxp_ke1xf512vlx16.dtsi:29 */
	};

	/* node '/leds' defined in zephyr/boards/nxp/twr_ke18f/twr_ke18f.dts:58 */
	leds {
		compatible = "gpio-leds"; /* in zephyr/boards/nxp/twr_ke18f/twr_ke18f.dts:59 */

		/* node '/leds/led_0' defined in zephyr/boards/nxp/twr_ke18f/twr_ke18f.dts:61 */
		orange_led: led_0 {
			gpios = < &gpioc 0xd 0x1 >; /* in zephyr/boards/nxp/twr_ke18f/twr_ke18f.dts:62 */
			label = "User LED D9";      /* in zephyr/boards/nxp/twr_ke18f/twr_ke18f.dts:63 */
		};

		/* node '/leds/led_1' defined in zephyr/boards/nxp/twr_ke18f/twr_ke18f.dts:66 */
		yellow_led: led_1 {
			gpios = < &gpioc 0xc 0x1 >; /* in zephyr/boards/nxp/twr_ke18f/twr_ke18f.dts:67 */
			label = "User LED D8";      /* in zephyr/boards/nxp/twr_ke18f/twr_ke18f.dts:68 */
		};

		/* node '/leds/led_2' defined in zephyr/boards/nxp/twr_ke18f/twr_ke18f.dts:71 */
		green_led: led_2 {
			gpios = < &gpioc 0xb 0x1 >; /* in zephyr/boards/nxp/twr_ke18f/twr_ke18f.dts:72 */
			label = "User LED D7";      /* in zephyr/boards/nxp/twr_ke18f/twr_ke18f.dts:73 */
		};

		/* node '/leds/led_3' defined in zephyr/boards/nxp/twr_ke18f/twr_ke18f.dts:76 */
		red_led: led_3 {
			gpios = < &gpioc 0xa 0x1 >; /* in zephyr/boards/nxp/twr_ke18f/twr_ke18f.dts:77 */
			label = "User LED D6";      /* in zephyr/boards/nxp/twr_ke18f/twr_ke18f.dts:78 */
		};

		/* node '/leds/led_4' defined in zephyr/boards/nxp/twr_ke18f/twr_ke18f.dts:81 */
		tri_red_led: led_4 {
			gpios = < &gpiod 0x10 0x1 >;          /* in zephyr/boards/nxp/twr_ke18f/twr_ke18f.dts:82 */
			label = "User Tricolor LED D5 (Red)"; /* in zephyr/boards/nxp/twr_ke18f/twr_ke18f.dts:83 */
		};

		/* node '/leds/led_5' defined in zephyr/boards/nxp/twr_ke18f/twr_ke18f.dts:86 */
		tri_green_led: led_5 {
			gpios = < &gpiod 0xf 0x1 >;             /* in zephyr/boards/nxp/twr_ke18f/twr_ke18f.dts:87 */
			label = "User Tricolor LED D5 (Green)"; /* in zephyr/boards/nxp/twr_ke18f/twr_ke18f.dts:88 */
		};

		/* node '/leds/led_6' defined in zephyr/boards/nxp/twr_ke18f/twr_ke18f.dts:91 */
		tri_blue_led: led_6 {
			gpios = < &gpiob 0x5 0x1 >;            /* in zephyr/boards/nxp/twr_ke18f/twr_ke18f.dts:92 */
			label = "User Tricolor LED D5 (Blue)"; /* in zephyr/boards/nxp/twr_ke18f/twr_ke18f.dts:93 */
		};
	};

	/* node '/pwmleds' defined in zephyr/boards/nxp/twr_ke18f/twr_ke18f.dts:97 */
	pwmleds {
		compatible = "pwm-leds"; /* in zephyr/boards/nxp/twr_ke18f/twr_ke18f.dts:98 */

		/* node '/pwmleds/led_pwm_0' defined in zephyr/boards/nxp/twr_ke18f/twr_ke18f.dts:100 */
		orange_pwm_led: led_pwm_0 {
			pwms = < &ftm3 0x7 0x1312d00 0x1 >; /* in zephyr/boards/nxp/twr_ke18f/twr_ke18f.dts:101 */
			label = "User PWM LED D9";          /* in zephyr/boards/nxp/twr_ke18f/twr_ke18f.dts:102 */
		};

		/* node '/pwmleds/led_pwm_1' defined in zephyr/boards/nxp/twr_ke18f/twr_ke18f.dts:105 */
		yellow_pwm_led: led_pwm_1 {
			pwms = < &ftm3 0x6 0x1312d00 0x1 >; /* in zephyr/boards/nxp/twr_ke18f/twr_ke18f.dts:106 */
			label = "User PWM LED D8";          /* in zephyr/boards/nxp/twr_ke18f/twr_ke18f.dts:107 */
		};

		/* node '/pwmleds/led_pwm_2' defined in zephyr/boards/nxp/twr_ke18f/twr_ke18f.dts:110 */
		green_pwm_led: led_pwm_2 {
			pwms = < &ftm3 0x5 0x1312d00 0x1 >; /* in zephyr/boards/nxp/twr_ke18f/twr_ke18f.dts:111 */
			label = "User PWM LED D7";          /* in zephyr/boards/nxp/twr_ke18f/twr_ke18f.dts:112 */
		};

		/* node '/pwmleds/led_pwm_3' defined in zephyr/boards/nxp/twr_ke18f/twr_ke18f.dts:115 */
		red_pwm_led: led_pwm_3 {
			pwms = < &ftm3 0x4 0x1312d00 0x1 >; /* in zephyr/boards/nxp/twr_ke18f/twr_ke18f.dts:116 */
			label = "User PWM LED D6";          /* in zephyr/boards/nxp/twr_ke18f/twr_ke18f.dts:117 */
		};

		/* node '/pwmleds/led_pwm_4' defined in zephyr/boards/nxp/twr_ke18f/twr_ke18f.dts:120 */
		tri_red_pwm_led: led_pwm_4 {
			pwms = < &ftm0 0x1 0x1312d00 0x1 >;       /* in zephyr/boards/nxp/twr_ke18f/twr_ke18f.dts:121 */
			label = "User Tricolor PWM LED D5 (Red)"; /* in zephyr/boards/nxp/twr_ke18f/twr_ke18f.dts:122 */
		};

		/* node '/pwmleds/led_pwm_5' defined in zephyr/boards/nxp/twr_ke18f/twr_ke18f.dts:125 */
		tri_green_pwm_led: led_pwm_5 {
			pwms = < &ftm0 0x0 0x1312d00 0x1 >;         /* in zephyr/boards/nxp/twr_ke18f/twr_ke18f.dts:126 */
			label = "User Tricolor PWM LED D5 (Green)"; /* in zephyr/boards/nxp/twr_ke18f/twr_ke18f.dts:127 */
		};

		/* node '/pwmleds/led_pwm_6' defined in zephyr/boards/nxp/twr_ke18f/twr_ke18f.dts:130 */
		tri_blue_pwm_led: led_pwm_6 {
			pwms = < &ftm0 0x5 0x1312d00 0x1 >;        /* in zephyr/boards/nxp/twr_ke18f/twr_ke18f.dts:131 */
			label = "User Tricolor PWM LED D5 (Blue)"; /* in zephyr/boards/nxp/twr_ke18f/twr_ke18f.dts:132 */
		};
	};

	/* node '/gpio_keys' defined in zephyr/boards/nxp/twr_ke18f/twr_ke18f.dts:136 */
	gpio_keys {
		compatible = "gpio-keys"; /* in zephyr/boards/nxp/twr_ke18f/twr_ke18f.dts:137 */

		/* node '/gpio_keys/button_0' defined in zephyr/boards/nxp/twr_ke18f/twr_ke18f.dts:139 */
		user_button_2: button_0 {
			label = "User SW2";         /* in zephyr/boards/nxp/twr_ke18f/twr_ke18f.dts:140 */
			gpios = < &gpiod 0x3 0x1 >; /* in zephyr/boards/nxp/twr_ke18f/twr_ke18f.dts:141 */
			zephyr,code = < 0xb >;      /* in zephyr/boards/nxp/twr_ke18f/twr_ke18f.dts:142 */
		};

		/* node '/gpio_keys/button_1' defined in zephyr/boards/nxp/twr_ke18f/twr_ke18f.dts:145 */
		user_button_3: button_1 {
			label = "User SW3";         /* in zephyr/boards/nxp/twr_ke18f/twr_ke18f.dts:146 */
			gpios = < &gpiod 0x6 0x1 >; /* in zephyr/boards/nxp/twr_ke18f/twr_ke18f.dts:147 */
			zephyr,code = < 0x2 >;      /* in zephyr/boards/nxp/twr_ke18f/twr_ke18f.dts:148 */
		};
	};
};
